VERSION ""

NS_ :

BS_:

BU_:

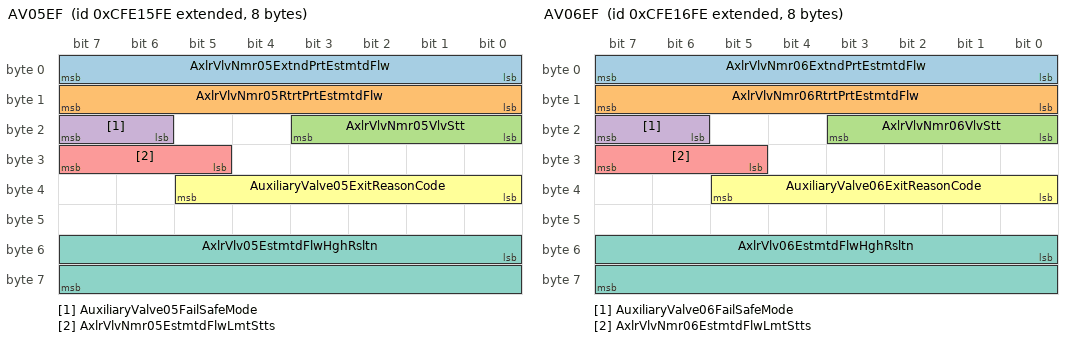
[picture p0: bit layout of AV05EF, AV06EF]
BO_ 2365462014 AV05EF: 8 Vector__XXX
 SG_ AxlrVlvNmr05ExtndPrtEstmtdFlw : 0|8@1+ (1,-125) [-125|125] "%" Vector__XXX
 SG_ AxlrVlvNmr05RtrtPrtEstmtdFlw : 8|8@1+ (1,-125) [-125|125] "%" Vector__XXX
 SG_ AxlrVlvNmr05VlvStt : 16|4@1+ (1,0) [0|15] "" Vector__XXX
 SG_ AuxiliaryValve05FailSafeMode : 22|2@1+ (1,0) [0|3] "" Vector__XXX
 SG_ AxlrVlvNmr05EstmtdFlwLmtStts : 29|3@1+ (1,0) [0|7] "" Vector__XXX
 SG_ AuxiliaryValve05ExitReasonCode : 32|6@1+ (1,0) [0|63] "" Vector__XXX
 SG_ AxlrVlv05EstmtdFlwHghRsltn : 48|16@1+ (0.004,-125) [-125|132.02] "%" Vector__XXX

BO_ 2365462270 AV06EF: 8 Vector__XXX
 SG_ AxlrVlvNmr06ExtndPrtEstmtdFlw : 0|8@1+ (1,-125) [-125|125] "%" Vector__XXX
 SG_ AxlrVlvNmr06RtrtPrtEstmtdFlw : 8|8@1+ (1,-125) [-125|125] "%" Vector__XXX
 SG_ AxlrVlvNmr06VlvStt : 16|4@1+ (1,0) [0|15] "" Vector__XXX
 SG_ AuxiliaryValve06FailSafeMode : 22|2@1+ (1,0) [0|3] "" Vector__XXX
 SG_ AxlrVlvNmr06EstmtdFlwLmtStts : 29|3@1+ (1,0) [0|7] "" Vector__XXX
 SG_ AuxiliaryValve06ExitReasonCode : 32|6@1+ (1,0) [0|63] "" Vector__XXX
 SG_ AxlrVlv06EstmtdFlwHghRsltn : 48|16@1+ (0.004,-125) [-125|132.02] "%" Vector__XXX

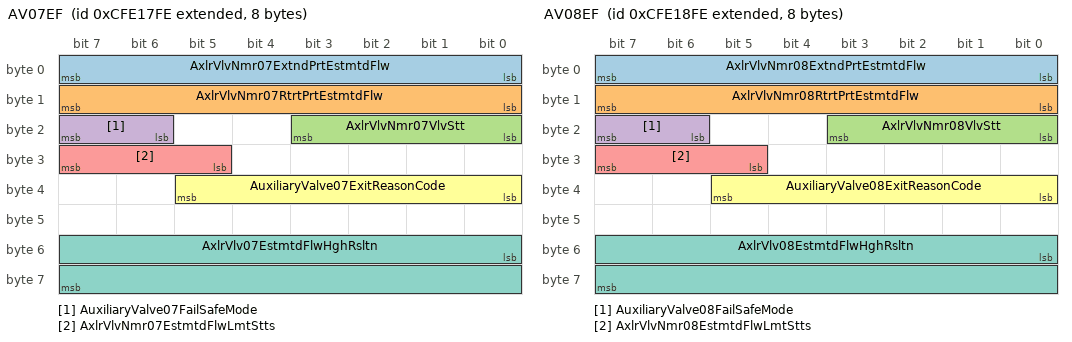
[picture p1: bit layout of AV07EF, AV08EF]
BO_ 2365462526 AV07EF: 8 Vector__XXX
 SG_ AxlrVlvNmr07ExtndPrtEstmtdFlw : 0|8@1+ (1,-125) [-125|125] "%" Vector__XXX
 SG_ AxlrVlvNmr07RtrtPrtEstmtdFlw : 8|8@1+ (1,-125) [-125|125] "%" Vector__XXX
 SG_ AxlrVlvNmr07VlvStt : 16|4@1+ (1,0) [0|15] "" Vector__XXX
 SG_ AuxiliaryValve07FailSafeMode : 22|2@1+ (1,0) [0|3] "" Vector__XXX
 SG_ AxlrVlvNmr07EstmtdFlwLmtStts : 29|3@1+ (1,0) [0|7] "" Vector__XXX
 SG_ AuxiliaryValve07ExitReasonCode : 32|6@1+ (1,0) [0|63] "" Vector__XXX
 SG_ AxlrVlv07EstmtdFlwHghRsltn : 48|16@1+ (0.004,-125) [-125|132.02] "%" Vector__XXX

BO_ 2365462782 AV08EF: 8 Vector__XXX
 SG_ AxlrVlvNmr08ExtndPrtEstmtdFlw : 0|8@1+ (1,-125) [-125|125] "%" Vector__XXX
 SG_ AxlrVlvNmr08RtrtPrtEstmtdFlw : 8|8@1+ (1,-125) [-125|125] "%" Vector__XXX
 SG_ AxlrVlvNmr08VlvStt : 16|4@1+ (1,0) [0|15] "" Vector__XXX
 SG_ AuxiliaryValve08FailSafeMode : 22|2@1+ (1,0) [0|3] "" Vector__XXX
 SG_ AxlrVlvNmr08EstmtdFlwLmtStts : 29|3@1+ (1,0) [0|7] "" Vector__XXX
 SG_ AuxiliaryValve08ExitReasonCode : 32|6@1+ (1,0) [0|63] "" Vector__XXX
 SG_ AxlrVlv08EstmtdFlwHghRsltn : 48|16@1+ (0.004,-125) [-125|132.02] "%" Vector__XXX

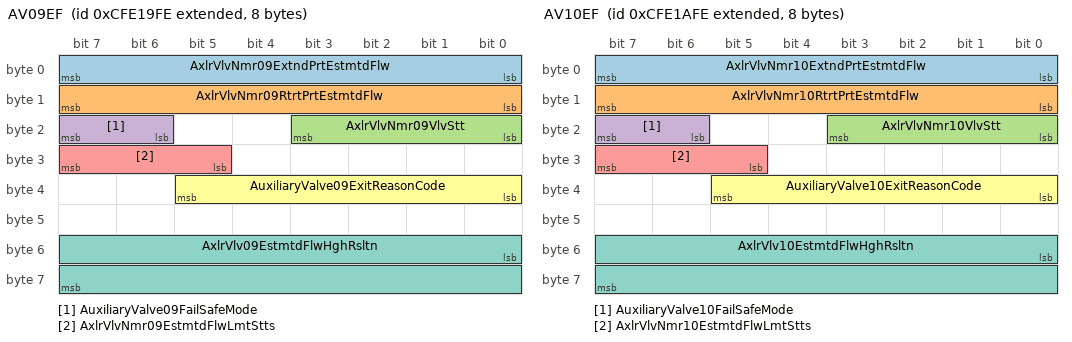
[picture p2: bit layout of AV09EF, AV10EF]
BO_ 2365463038 AV09EF: 8 Vector__XXX
 SG_ AxlrVlvNmr09ExtndPrtEstmtdFlw : 0|8@1+ (1,-125) [-125|125] "%" Vector__XXX
 SG_ AxlrVlvNmr09RtrtPrtEstmtdFlw : 8|8@1+ (1,-125) [-125|125] "%" Vector__XXX
 SG_ AxlrVlvNmr09VlvStt : 16|4@1+ (1,0) [0|15] "" Vector__XXX
 SG_ AuxiliaryValve09FailSafeMode : 22|2@1+ (1,0) [0|3] "" Vector__XXX
 SG_ AxlrVlvNmr09EstmtdFlwLmtStts : 29|3@1+ (1,0) [0|7] "" Vector__XXX
 SG_ AuxiliaryValve09ExitReasonCode : 32|6@1+ (1,0) [0|63] "" Vector__XXX
 SG_ AxlrVlv09EstmtdFlwHghRsltn : 48|16@1+ (0.004,-125) [-125|132.02] "%" Vector__XXX

BO_ 2365463294 AV10EF: 8 Vector__XXX
 SG_ AxlrVlvNmr10ExtndPrtEstmtdFlw : 0|8@1+ (1,-125) [-125|125] "%" Vector__XXX
 SG_ AxlrVlvNmr10RtrtPrtEstmtdFlw : 8|8@1+ (1,-125) [-125|125] "%" Vector__XXX
 SG_ AxlrVlvNmr10VlvStt : 16|4@1+ (1,0) [0|15] "" Vector__XXX
 SG_ AuxiliaryValve10FailSafeMode : 22|2@1+ (1,0) [0|3] "" Vector__XXX
 SG_ AxlrVlvNmr10EstmtdFlwLmtStts : 29|3@1+ (1,0) [0|7] "" Vector__XXX
 SG_ AuxiliaryValve10ExitReasonCode : 32|6@1+ (1,0) [0|63] "" Vector__XXX
 SG_ AxlrVlv10EstmtdFlwHghRsltn : 48|16@1+ (0.004,-125) [-125|132.02] "%" Vector__XXX

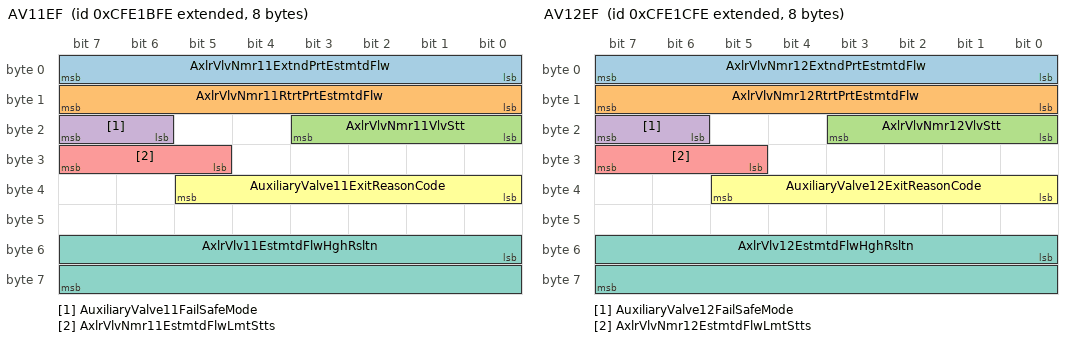
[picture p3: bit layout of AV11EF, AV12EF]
BO_ 2365463550 AV11EF: 8 Vector__XXX
 SG_ AxlrVlvNmr11ExtndPrtEstmtdFlw : 0|8@1+ (1,-125) [-125|125] "%" Vector__XXX
 SG_ AxlrVlvNmr11RtrtPrtEstmtdFlw : 8|8@1+ (1,-125) [-125|125] "%" Vector__XXX
 SG_ AxlrVlvNmr11VlvStt : 16|4@1+ (1,0) [0|15] "" Vector__XXX
 SG_ AuxiliaryValve11FailSafeMode : 22|2@1+ (1,0) [0|3] "" Vector__XXX
 SG_ AxlrVlvNmr11EstmtdFlwLmtStts : 29|3@1+ (1,0) [0|7] "" Vector__XXX
 SG_ AuxiliaryValve11ExitReasonCode : 32|6@1+ (1,0) [0|63] "" Vector__XXX
 SG_ AxlrVlv11EstmtdFlwHghRsltn : 48|16@1+ (0.004,-125) [-125|132.02] "%" Vector__XXX

BO_ 2365463806 AV12EF: 8 Vector__XXX
 SG_ AxlrVlvNmr12ExtndPrtEstmtdFlw : 0|8@1+ (1,-125) [-125|125] "%" Vector__XXX
 SG_ AxlrVlvNmr12RtrtPrtEstmtdFlw : 8|8@1+ (1,-125) [-125|125] "%" Vector__XXX
 SG_ AxlrVlvNmr12VlvStt : 16|4@1+ (1,0) [0|15] "" Vector__XXX
 SG_ AuxiliaryValve12FailSafeMode : 22|2@1+ (1,0) [0|3] "" Vector__XXX
 SG_ AxlrVlvNmr12EstmtdFlwLmtStts : 29|3@1+ (1,0) [0|7] "" Vector__XXX
 SG_ AuxiliaryValve12ExitReasonCode : 32|6@1+ (1,0) [0|63] "" Vector__XXX
 SG_ AxlrVlv12EstmtdFlwHghRsltn : 48|16@1+ (0.004,-125) [-125|132.02] "%" Vector__XXX

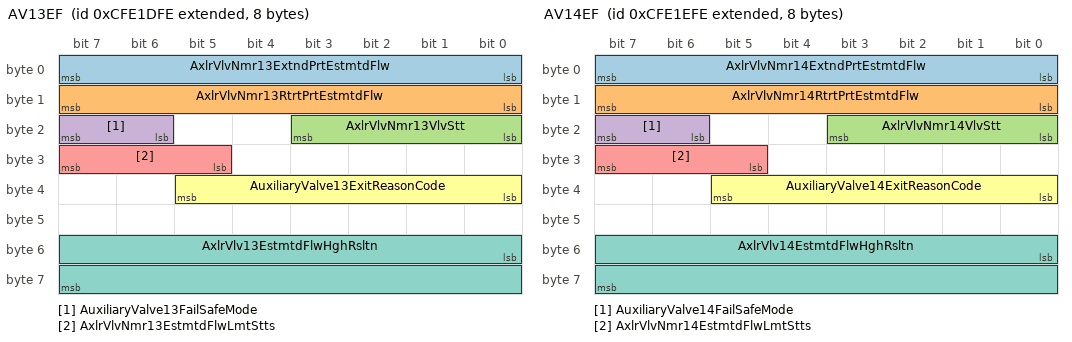
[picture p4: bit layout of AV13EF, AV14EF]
BO_ 2365464062 AV13EF: 8 Vector__XXX
 SG_ AxlrVlvNmr13ExtndPrtEstmtdFlw : 0|8@1+ (1,-125) [-125|125] "%" Vector__XXX
 SG_ AxlrVlvNmr13RtrtPrtEstmtdFlw : 8|8@1+ (1,-125) [-125|125] "%" Vector__XXX
 SG_ AxlrVlvNmr13VlvStt : 16|4@1+ (1,0) [0|15] "" Vector__XXX
 SG_ AuxiliaryValve13FailSafeMode : 22|2@1+ (1,0) [0|3] "" Vector__XXX
 SG_ AxlrVlvNmr13EstmtdFlwLmtStts : 29|3@1+ (1,0) [0|7] "" Vector__XXX
 SG_ AuxiliaryValve13ExitReasonCode : 32|6@1+ (1,0) [0|63] "" Vector__XXX
 SG_ AxlrVlv13EstmtdFlwHghRsltn : 48|16@1+ (0.004,-125) [-125|132.02] "%" Vector__XXX

BO_ 2365464318 AV14EF: 8 Vector__XXX
 SG_ AxlrVlvNmr14ExtndPrtEstmtdFlw : 0|8@1+ (1,-125) [-125|125] "%" Vector__XXX
 SG_ AxlrVlvNmr14RtrtPrtEstmtdFlw : 8|8@1+ (1,-125) [-125|125] "%" Vector__XXX
 SG_ AxlrVlvNmr14VlvStt : 16|4@1+ (1,0) [0|15] "" Vector__XXX
 SG_ AuxiliaryValve14FailSafeMode : 22|2@1+ (1,0) [0|3] "" Vector__XXX
 SG_ AxlrVlvNmr14EstmtdFlwLmtStts : 29|3@1+ (1,0) [0|7] "" Vector__XXX
 SG_ AuxiliaryValve14ExitReasonCode : 32|6@1+ (1,0) [0|63] "" Vector__XXX
 SG_ AxlrVlv14EstmtdFlwHghRsltn : 48|16@1+ (0.004,-125) [-125|132.02] "%" Vector__XXX

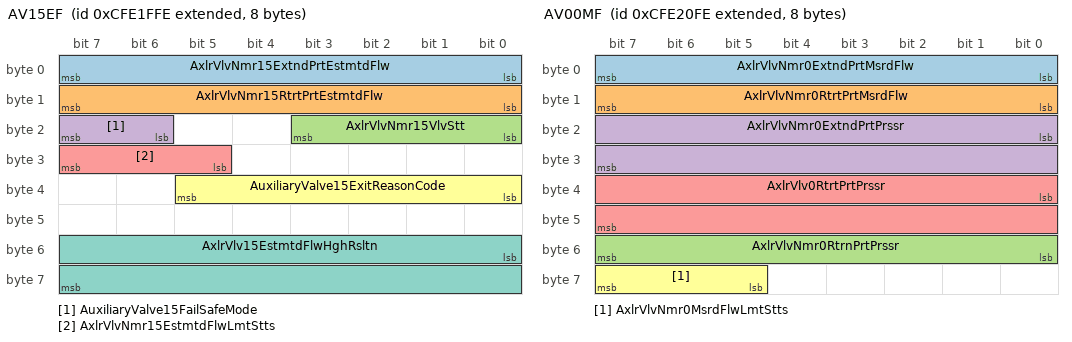
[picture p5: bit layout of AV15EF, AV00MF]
BO_ 2365464574 AV15EF: 8 Vector__XXX
 SG_ AxlrVlvNmr15ExtndPrtEstmtdFlw : 0|8@1+ (1,-125) [-125|125] "%" Vector__XXX
 SG_ AxlrVlvNmr15RtrtPrtEstmtdFlw : 8|8@1+ (1,-125) [-125|125] "%" Vector__XXX
 SG_ AxlrVlvNmr15VlvStt : 16|4@1+ (1,0) [0|15] "" Vector__XXX
 SG_ AuxiliaryValve15FailSafeMode : 22|2@1+ (1,0) [0|3] "" Vector__XXX
 SG_ AxlrVlvNmr15EstmtdFlwLmtStts : 29|3@1+ (1,0) [0|7] "" Vector__XXX
 SG_ AuxiliaryValve15ExitReasonCode : 32|6@1+ (1,0) [0|63] "" Vector__XXX
 SG_ AxlrVlv15EstmtdFlwHghRsltn : 48|16@1+ (0.004,-125) [-125|132.02] "%" Vector__XXX

BO_ 2365464830 AV00MF: 8 Vector__XXX
 SG_ AxlrVlvNmr0ExtndPrtMsrdFlw : 0|8@1+ (1,-125) [-125|125] "%" Vector__XXX
 SG_ AxlrVlvNmr0RtrtPrtMsrdFlw : 8|8@1+ (1,-125) [-125|125] "%" Vector__XXX
 SG_ AxlrVlvNmr0RtrnPrtPrssr : 48|8@1+ (16,0) [0|4000] "kPa" Vector__XXX
 SG_ AxlrVlvNmr0ExtndPrtPrssr : 16|16@1+ (5,0) [0|321275] "kPa" Vector__XXX
 SG_ AxlrVlv0RtrtPrtPrssr : 32|16@1+ (5,0) [0|321275] "kPa" Vector__XXX
 SG_ AxlrVlvNmr0MsrdFlwLmtStts : 61|3@1+ (1,0) [0|7] "" Vector__XXX

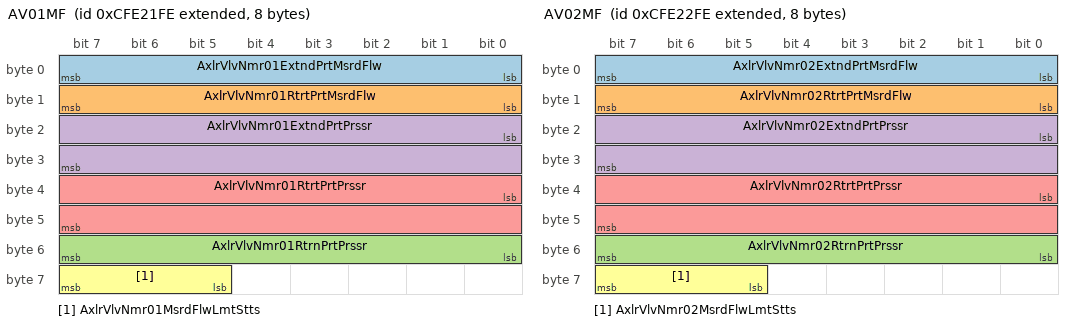
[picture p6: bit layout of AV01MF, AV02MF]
BO_ 2365465086 AV01MF: 8 Vector__XXX
 SG_ AxlrVlvNmr01ExtndPrtMsrdFlw : 0|8@1+ (1,-125) [-125|125] "%" Vector__XXX
 SG_ AxlrVlvNmr01RtrtPrtMsrdFlw : 8|8@1+ (1,-125) [-125|125] "%" Vector__XXX
 SG_ AxlrVlvNmr01RtrnPrtPrssr : 48|8@1+ (16,0) [0|4000] "kPa" Vector__XXX
 SG_ AxlrVlvNmr01ExtndPrtPrssr : 16|16@1+ (5,0) [0|321275] "kPa" Vector__XXX
 SG_ AxlrVlvNmr01RtrtPrtPrssr : 32|16@1+ (5,0) [0|321275] "kPa" Vector__XXX
 SG_ AxlrVlvNmr01MsrdFlwLmtStts : 61|3@1+ (1,0) [0|7] "" Vector__XXX

BO_ 2365465342 AV02MF: 8 Vector__XXX
 SG_ AxlrVlvNmr02ExtndPrtMsrdFlw : 0|8@1+ (1,-125) [-125|125] "%" Vector__XXX
 SG_ AxlrVlvNmr02RtrtPrtMsrdFlw : 8|8@1+ (1,-125) [-125|125] "%" Vector__XXX
 SG_ AxlrVlvNmr02RtrnPrtPrssr : 48|8@1+ (16,0) [0|4000] "kPa" Vector__XXX
 SG_ AxlrVlvNmr02ExtndPrtPrssr : 16|16@1+ (5,0) [0|321275] "kPa" Vector__XXX
 SG_ AxlrVlvNmr02RtrtPrtPrssr : 32|16@1+ (5,0) [0|321275] "kPa" Vector__XXX
 SG_ AxlrVlvNmr02MsrdFlwLmtStts : 61|3@1+ (1,0) [0|7] "" Vector__XXX

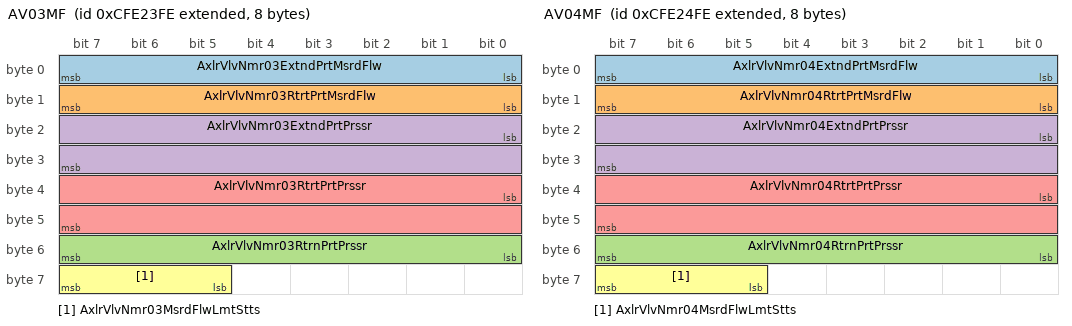
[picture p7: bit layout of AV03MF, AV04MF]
BO_ 2365465598 AV03MF: 8 Vector__XXX
 SG_ AxlrVlvNmr03ExtndPrtMsrdFlw : 0|8@1+ (1,-125) [-125|125] "%" Vector__XXX
 SG_ AxlrVlvNmr03RtrtPrtMsrdFlw : 8|8@1+ (1,-125) [-125|125] "%" Vector__XXX
 SG_ AxlrVlvNmr03RtrnPrtPrssr : 48|8@1+ (16,0) [0|4000] "kPa" Vector__XXX
 SG_ AxlrVlvNmr03ExtndPrtPrssr : 16|16@1+ (5,0) [0|321275] "kPa" Vector__XXX
 SG_ AxlrVlvNmr03RtrtPrtPrssr : 32|16@1+ (5,0) [0|321275] "kPa" Vector__XXX
 SG_ AxlrVlvNmr03MsrdFlwLmtStts : 61|3@1+ (1,0) [0|7] "" Vector__XXX

BO_ 2365465854 AV04MF: 8 Vector__XXX
 SG_ AxlrVlvNmr04ExtndPrtMsrdFlw : 0|8@1+ (1,-125) [-125|125] "%" Vector__XXX
 SG_ AxlrVlvNmr04RtrtPrtMsrdFlw : 8|8@1+ (1,-125) [-125|125] "%" Vector__XXX
 SG_ AxlrVlvNmr04RtrnPrtPrssr : 48|8@1+ (16,0) [0|4000] "kPa" Vector__XXX
 SG_ AxlrVlvNmr04ExtndPrtPrssr : 16|16@1+ (5,0) [0|321275] "kPa" Vector__XXX
 SG_ AxlrVlvNmr04RtrtPrtPrssr : 32|16@1+ (5,0) [0|321275] "kPa" Vector__XXX
 SG_ AxlrVlvNmr04MsrdFlwLmtStts : 61|3@1+ (1,0) [0|7] "" Vector__XXX

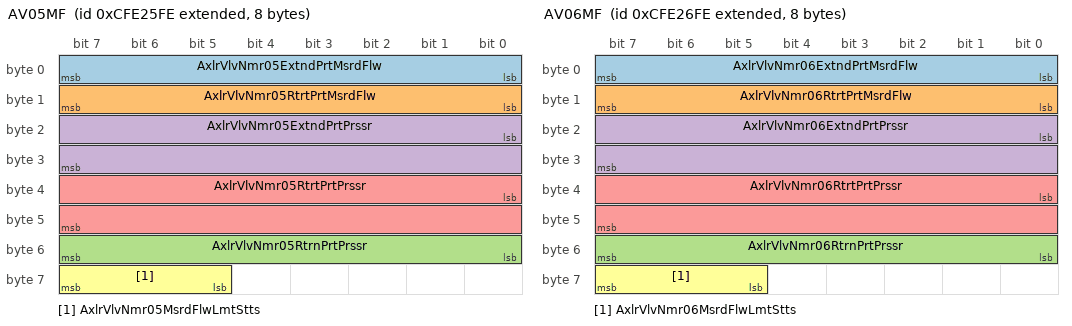
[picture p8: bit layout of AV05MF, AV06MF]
BO_ 2365466110 AV05MF: 8 Vector__XXX
 SG_ AxlrVlvNmr05ExtndPrtMsrdFlw : 0|8@1+ (1,-125) [-125|125] "%" Vector__XXX
 SG_ AxlrVlvNmr05RtrtPrtMsrdFlw : 8|8@1+ (1,-125) [-125|125] "%" Vector__XXX
 SG_ AxlrVlvNmr05RtrnPrtPrssr : 48|8@1+ (16,0) [0|4000] "kPa" Vector__XXX
 SG_ AxlrVlvNmr05ExtndPrtPrssr : 16|16@1+ (5,0) [0|321275] "kPa" Vector__XXX
 SG_ AxlrVlvNmr05RtrtPrtPrssr : 32|16@1+ (5,0) [0|321275] "kPa" Vector__XXX
 SG_ AxlrVlvNmr05MsrdFlwLmtStts : 61|3@1+ (1,0) [0|7] "" Vector__XXX

BO_ 2365466366 AV06MF: 8 Vector__XXX
 SG_ AxlrVlvNmr06ExtndPrtMsrdFlw : 0|8@1+ (1,-125) [-125|125] "%" Vector__XXX
 SG_ AxlrVlvNmr06RtrtPrtMsrdFlw : 8|8@1+ (1,-125) [-125|125] "%" Vector__XXX
 SG_ AxlrVlvNmr06RtrnPrtPrssr : 48|8@1+ (16,0) [0|4000] "kPa" Vector__XXX
 SG_ AxlrVlvNmr06ExtndPrtPrssr : 16|16@1+ (5,0) [0|321275] "kPa" Vector__XXX
 SG_ AxlrVlvNmr06RtrtPrtPrssr : 32|16@1+ (5,0) [0|321275] "kPa" Vector__XXX
 SG_ AxlrVlvNmr06MsrdFlwLmtStts : 61|3@1+ (1,0) [0|7] "" Vector__XXX

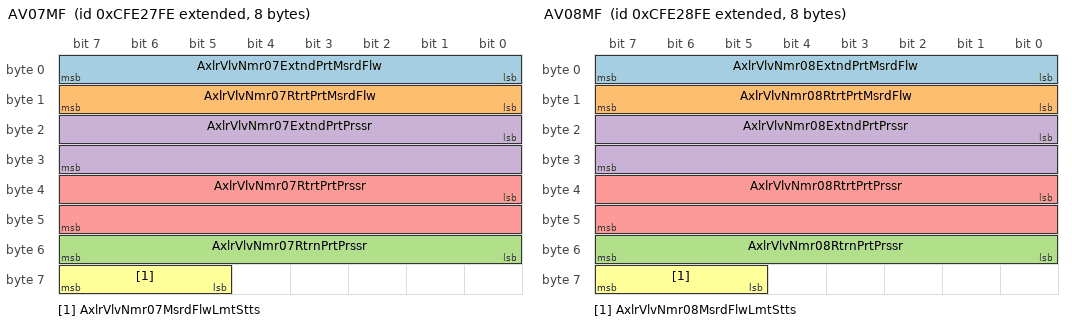
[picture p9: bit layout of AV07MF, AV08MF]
BO_ 2365466622 AV07MF: 8 Vector__XXX
 SG_ AxlrVlvNmr07ExtndPrtMsrdFlw : 0|8@1+ (1,-125) [-125|125] "%" Vector__XXX
 SG_ AxlrVlvNmr07RtrtPrtMsrdFlw : 8|8@1+ (1,-125) [-125|125] "%" Vector__XXX
 SG_ AxlrVlvNmr07RtrnPrtPrssr : 48|8@1+ (16,0) [0|4000] "kPa" Vector__XXX
 SG_ AxlrVlvNmr07ExtndPrtPrssr : 16|16@1+ (5,0) [0|321275] "kPa" Vector__XXX
 SG_ AxlrVlvNmr07RtrtPrtPrssr : 32|16@1+ (5,0) [0|321275] "kPa" Vector__XXX
 SG_ AxlrVlvNmr07MsrdFlwLmtStts : 61|3@1+ (1,0) [0|7] "" Vector__XXX

BO_ 2365466878 AV08MF: 8 Vector__XXX
 SG_ AxlrVlvNmr08ExtndPrtMsrdFlw : 0|8@1+ (1,-125) [-125|125] "%" Vector__XXX
 SG_ AxlrVlvNmr08RtrtPrtMsrdFlw : 8|8@1+ (1,-125) [-125|125] "%" Vector__XXX
 SG_ AxlrVlvNmr08RtrnPrtPrssr : 48|8@1+ (16,0) [0|4000] "kPa" Vector__XXX
 SG_ AxlrVlvNmr08ExtndPrtPrssr : 16|16@1+ (5,0) [0|321275] "kPa" Vector__XXX
 SG_ AxlrVlvNmr08RtrtPrtPrssr : 32|16@1+ (5,0) [0|321275] "kPa" Vector__XXX
 SG_ AxlrVlvNmr08MsrdFlwLmtStts : 61|3@1+ (1,0) [0|7] "" Vector__XXX

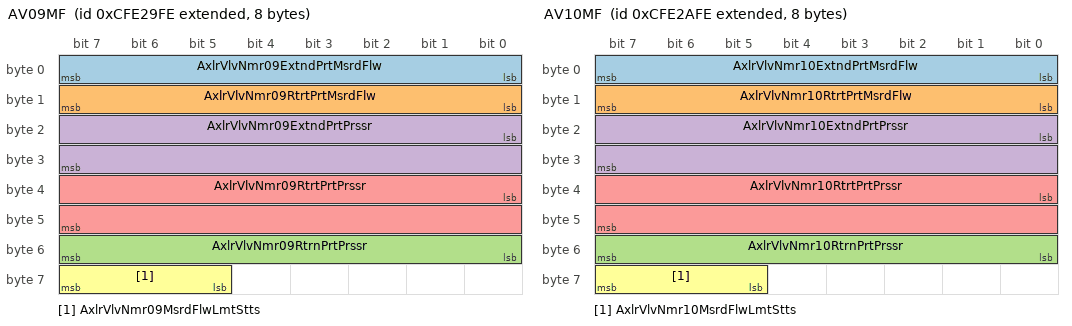
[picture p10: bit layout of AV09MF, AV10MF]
BO_ 2365467134 AV09MF: 8 Vector__XXX
 SG_ AxlrVlvNmr09ExtndPrtMsrdFlw : 0|8@1+ (1,-125) [-125|125] "%" Vector__XXX
 SG_ AxlrVlvNmr09RtrtPrtMsrdFlw : 8|8@1+ (1,-125) [-125|125] "%" Vector__XXX
 SG_ AxlrVlvNmr09RtrnPrtPrssr : 48|8@1+ (16,0) [0|4000] "kPa" Vector__XXX
 SG_ AxlrVlvNmr09ExtndPrtPrssr : 16|16@1+ (5,0) [0|321275] "kPa" Vector__XXX
 SG_ AxlrVlvNmr09RtrtPrtPrssr : 32|16@1+ (5,0) [0|321275] "kPa" Vector__XXX
 SG_ AxlrVlvNmr09MsrdFlwLmtStts : 61|3@1+ (1,0) [0|7] "" Vector__XXX

BO_ 2365467390 AV10MF: 8 Vector__XXX
 SG_ AxlrVlvNmr10ExtndPrtMsrdFlw : 0|8@1+ (1,-125) [-125|125] "%" Vector__XXX
 SG_ AxlrVlvNmr10RtrtPrtMsrdFlw : 8|8@1+ (1,-125) [-125|125] "%" Vector__XXX
 SG_ AxlrVlvNmr10RtrnPrtPrssr : 48|8@1+ (16,0) [0|4000] "kPa" Vector__XXX
 SG_ AxlrVlvNmr10ExtndPrtPrssr : 16|16@1+ (5,0) [0|321275] "kPa" Vector__XXX
 SG_ AxlrVlvNmr10RtrtPrtPrssr : 32|16@1+ (5,0) [0|321275] "kPa" Vector__XXX
 SG_ AxlrVlvNmr10MsrdFlwLmtStts : 61|3@1+ (1,0) [0|7] "" Vector__XXX

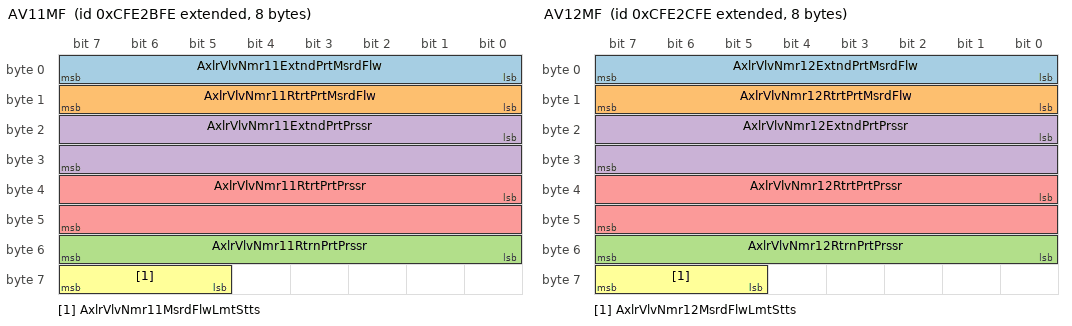
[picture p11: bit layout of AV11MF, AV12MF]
BO_ 2365467646 AV11MF: 8 Vector__XXX
 SG_ AxlrVlvNmr11ExtndPrtMsrdFlw : 0|8@1+ (1,-125) [-125|125] "%" Vector__XXX
 SG_ AxlrVlvNmr11RtrtPrtMsrdFlw : 8|8@1+ (1,-125) [-125|125] "%" Vector__XXX
 SG_ AxlrVlvNmr11RtrnPrtPrssr : 48|8@1+ (16,0) [0|4000] "kPa" Vector__XXX
 SG_ AxlrVlvNmr11ExtndPrtPrssr : 16|16@1+ (5,0) [0|321275] "kPa" Vector__XXX
 SG_ AxlrVlvNmr11RtrtPrtPrssr : 32|16@1+ (5,0) [0|321275] "kPa" Vector__XXX
 SG_ AxlrVlvNmr11MsrdFlwLmtStts : 61|3@1+ (1,0) [0|7] "" Vector__XXX

BO_ 2365467902 AV12MF: 8 Vector__XXX
 SG_ AxlrVlvNmr12ExtndPrtMsrdFlw : 0|8@1+ (1,-125) [-125|125] "%" Vector__XXX
 SG_ AxlrVlvNmr12RtrtPrtMsrdFlw : 8|8@1+ (1,-125) [-125|125] "%" Vector__XXX
 SG_ AxlrVlvNmr12RtrnPrtPrssr : 48|8@1+ (16,0) [0|4000] "kPa" Vector__XXX
 SG_ AxlrVlvNmr12ExtndPrtPrssr : 16|16@1+ (5,0) [0|321275] "kPa" Vector__XXX
 SG_ AxlrVlvNmr12RtrtPrtPrssr : 32|16@1+ (5,0) [0|321275] "kPa" Vector__XXX
 SG_ AxlrVlvNmr12MsrdFlwLmtStts : 61|3@1+ (1,0) [0|7] "" Vector__XXX

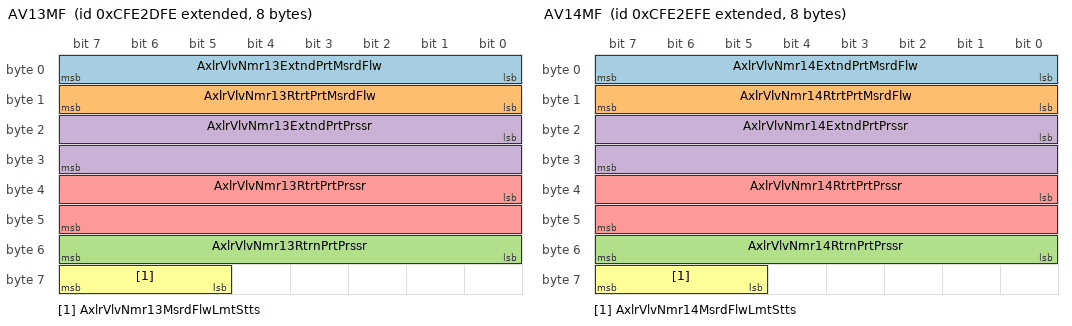
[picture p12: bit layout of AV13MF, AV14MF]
BO_ 2365468158 AV13MF: 8 Vector__XXX
 SG_ AxlrVlvNmr13ExtndPrtMsrdFlw : 0|8@1+ (1,-125) [-125|125] "%" Vector__XXX
 SG_ AxlrVlvNmr13RtrtPrtMsrdFlw : 8|8@1+ (1,-125) [-125|125] "%" Vector__XXX
 SG_ AxlrVlvNmr13RtrnPrtPrssr : 48|8@1+ (16,0) [0|4000] "kPa" Vector__XXX
 SG_ AxlrVlvNmr13ExtndPrtPrssr : 16|16@1+ (5,0) [0|321275] "kPa" Vector__XXX
 SG_ AxlrVlvNmr13RtrtPrtPrssr : 32|16@1+ (5,0) [0|321275] "kPa" Vector__XXX
 SG_ AxlrVlvNmr13MsrdFlwLmtStts : 61|3@1+ (1,0) [0|7] "" Vector__XXX

BO_ 2365468414 AV14MF: 8 Vector__XXX
 SG_ AxlrVlvNmr14ExtndPrtMsrdFlw : 0|8@1+ (1,-125) [-125|125] "%" Vector__XXX
 SG_ AxlrVlvNmr14RtrtPrtMsrdFlw : 8|8@1+ (1,-125) [-125|125] "%" Vector__XXX
 SG_ AxlrVlvNmr14RtrnPrtPrssr : 48|8@1+ (16,0) [0|4000] "kPa" Vector__XXX
 SG_ AxlrVlvNmr14ExtndPrtPrssr : 16|16@1+ (5,0) [0|321275] "kPa" Vector__XXX
 SG_ AxlrVlvNmr14RtrtPrtPrssr : 32|16@1+ (5,0) [0|321275] "kPa" Vector__XXX
 SG_ AxlrVlvNmr14MsrdFlwLmtStts : 61|3@1+ (1,0) [0|7] "" Vector__XXX

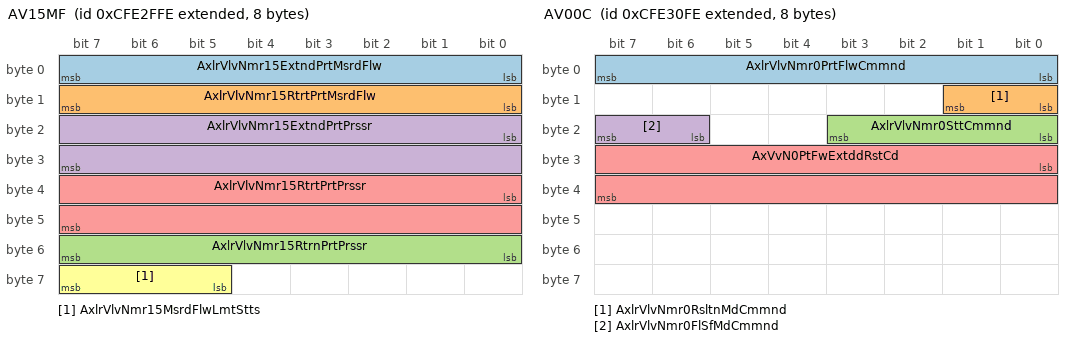
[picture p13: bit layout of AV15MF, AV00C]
BO_ 2365468670 AV15MF: 8 Vector__XXX
 SG_ AxlrVlvNmr15ExtndPrtMsrdFlw : 0|8@1+ (1,-125) [-125|125] "%" Vector__XXX
 SG_ AxlrVlvNmr15RtrtPrtMsrdFlw : 8|8@1+ (1,-125) [-125|125] "%" Vector__XXX
 SG_ AxlrVlvNmr15RtrnPrtPrssr : 48|8@1+ (16,0) [0|4000] "kPa" Vector__XXX
 SG_ AxlrVlvNmr15ExtndPrtPrssr : 16|16@1+ (5,0) [0|321275] "kPa" Vector__XXX
 SG_ AxlrVlvNmr15RtrtPrtPrssr : 32|16@1+ (5,0) [0|321275] "kPa" Vector__XXX
 SG_ AxlrVlvNmr15MsrdFlwLmtStts : 61|3@1+ (1,0) [0|7] "" Vector__XXX

BO_ 2365468926 AV00C: 8 Vector__XXX
 SG_ AxlrVlvNmr0PrtFlwCmmnd : 0|8@1+ (0.4,0) [0|100] "%" Vector__XXX
 SG_ AxlrVlvNmr0RsltnMdCmmnd : 8|2@1+ (1,0) [0|3] "" Vector__XXX
 SG_ AxlrVlvNmr0SttCmmnd : 16|4@1+ (1,0) [0|15] "" Vector__XXX
 SG_ AxlrVlvNmr0FlSfMdCmmnd : 22|2@1+ (1,0) [0|3] "" Vector__XXX
 SG_ AxVvN0PtFwExtddRstCd : 24|16@1+ (0.0015625,0) [0|100.3984375] "%" Vector__XXX

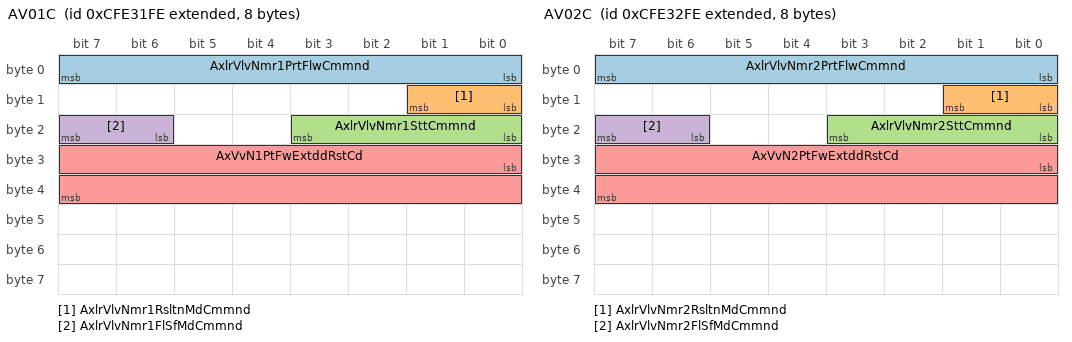
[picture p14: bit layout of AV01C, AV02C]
BO_ 2365469182 AV01C: 8 Vector__XXX
 SG_ AxlrVlvNmr1PrtFlwCmmnd : 0|8@1+ (0.4,0) [0|100] "%" Vector__XXX
 SG_ AxlrVlvNmr1RsltnMdCmmnd : 8|2@1+ (1,0) [0|3] "" Vector__XXX
 SG_ AxlrVlvNmr1SttCmmnd : 16|4@1+ (1,0) [0|15] "" Vector__XXX
 SG_ AxlrVlvNmr1FlSfMdCmmnd : 22|2@1+ (1,0) [0|3] "" Vector__XXX
 SG_ AxVvN1PtFwExtddRstCd : 24|16@1+ (0.0015625,0) [0|100.3984375] "%" Vector__XXX

BO_ 2365469438 AV02C: 8 Vector__XXX
 SG_ AxlrVlvNmr2PrtFlwCmmnd : 0|8@1+ (0.4,0) [0|100] "%" Vector__XXX
 SG_ AxlrVlvNmr2RsltnMdCmmnd : 8|2@1+ (1,0) [0|3] "" Vector__XXX
 SG_ AxlrVlvNmr2SttCmmnd : 16|4@1+ (1,0) [0|15] "" Vector__XXX
 SG_ AxlrVlvNmr2FlSfMdCmmnd : 22|2@1+ (1,0) [0|3] "" Vector__XXX
 SG_ AxVvN2PtFwExtddRstCd : 24|16@1+ (0.0015625,0) [0|100.3984375] "%" Vector__XXX

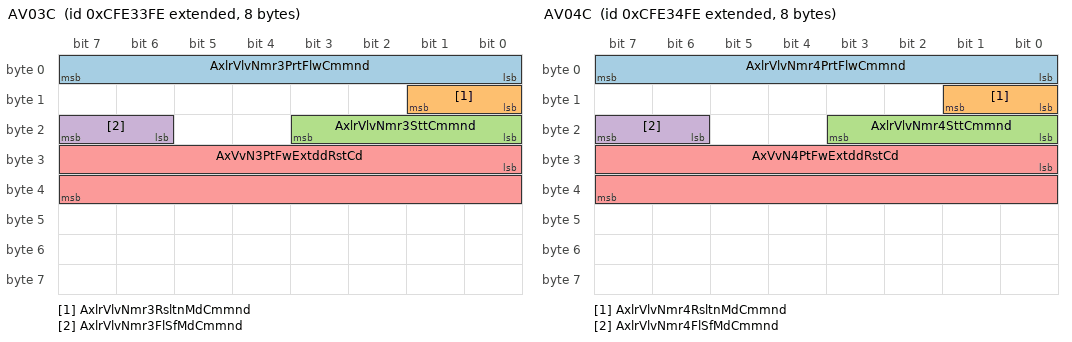
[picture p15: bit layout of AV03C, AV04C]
BO_ 2365469694 AV03C: 8 Vector__XXX
 SG_ AxlrVlvNmr3PrtFlwCmmnd : 0|8@1+ (0.4,0) [0|100] "%" Vector__XXX
 SG_ AxlrVlvNmr3RsltnMdCmmnd : 8|2@1+ (1,0) [0|3] "" Vector__XXX
 SG_ AxlrVlvNmr3SttCmmnd : 16|4@1+ (1,0) [0|15] "" Vector__XXX
 SG_ AxlrVlvNmr3FlSfMdCmmnd : 22|2@1+ (1,0) [0|3] "" Vector__XXX
 SG_ AxVvN3PtFwExtddRstCd : 24|16@1+ (0.0015625,0) [0|100.3984375] "%" Vector__XXX

BO_ 2365469950 AV04C: 8 Vector__XXX
 SG_ AxlrVlvNmr4PrtFlwCmmnd : 0|8@1+ (0.4,0) [0|100] "%" Vector__XXX
 SG_ AxlrVlvNmr4RsltnMdCmmnd : 8|2@1+ (1,0) [0|3] "" Vector__XXX
 SG_ AxlrVlvNmr4SttCmmnd : 16|4@1+ (1,0) [0|15] "" Vector__XXX
 SG_ AxlrVlvNmr4FlSfMdCmmnd : 22|2@1+ (1,0) [0|3] "" Vector__XXX
 SG_ AxVvN4PtFwExtddRstCd : 24|16@1+ (0.0015625,0) [0|100.3984375] "%" Vector__XXX

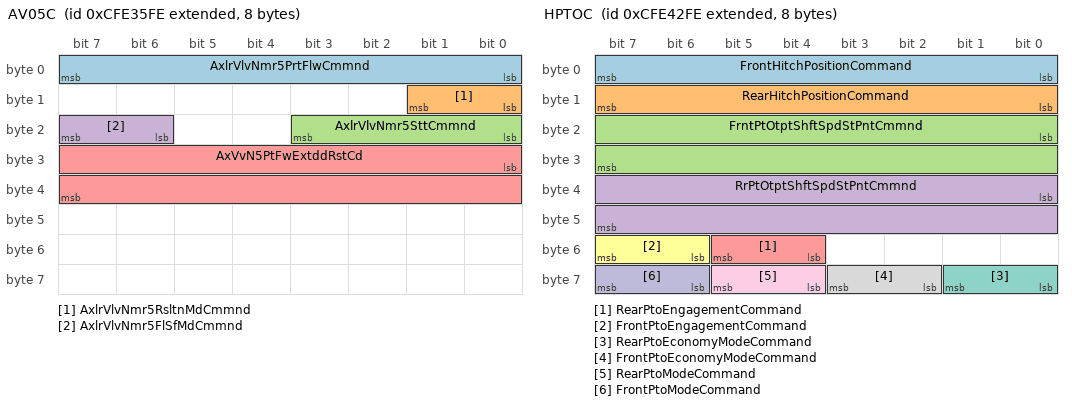
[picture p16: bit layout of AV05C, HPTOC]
BO_ 2365470206 AV05C: 8 Vector__XXX
 SG_ AxlrVlvNmr5PrtFlwCmmnd : 0|8@1+ (0.4,0) [0|100] "%" Vector__XXX
 SG_ AxlrVlvNmr5RsltnMdCmmnd : 8|2@1+ (1,0) [0|3] "" Vector__XXX
 SG_ AxlrVlvNmr5SttCmmnd : 16|4@1+ (1,0) [0|15] "" Vector__XXX
 SG_ AxlrVlvNmr5FlSfMdCmmnd : 22|2@1+ (1,0) [0|3] "" Vector__XXX
 SG_ AxVvN5PtFwExtddRstCd : 24|16@1+ (0.0015625,0) [0|100.3984375] "%" Vector__XXX

BO_ 2365470462 AV06C: 8 Vector__XXX
 SG_ AxlrVlvNmr6PrtFlwCmmnd : 0|8@1+ (0.4,0) [0|100] "%" Vector__XXX
 SG_ AxlrVlvNmr6RsltnMdCmmnd : 8|2@1+ (1,0) [0|3] "" Vector__XXX
 SG_ AxlrVlvNmr6SttCmmnd : 16|4@1+ (1,0) [0|15] "" Vector__XXX
 SG_ AxlrVlvNmr6FlSfMdCmmnd : 22|2@1+ (1,0) [0|3] "" Vector__XXX
 SG_ AxVvN6PtFwExtddRstCd : 24|16@1+ (0.0015625,0) [0|100.3984375] "%" Vector__XXX

BO_ 2365470718 AV07C: 8 Vector__XXX
 SG_ AxlrVlvNmr7PrtFlwCmmnd : 0|8@1+ (0.4,0) [0|100] "%" Vector__XXX
 SG_ AxlrVlvNmr7RsltnMdCmmnd : 8|2@1+ (1,0) [0|3] "" Vector__XXX
 SG_ AxlrVlvNmr7SttCmmnd : 16|4@1+ (1,0) [0|15] "" Vector__XXX
 SG_ AxlrVlvNmr7FlSfMdCmmnd : 22|2@1+ (1,0) [0|3] "" Vector__XXX
 SG_ AxVvN7PtFwExtddRstCd : 24|16@1+ (0.0015625,0) [0|100.3984375] "%" Vector__XXX

BO_ 2365470974 AV08C: 8 Vector__XXX
 SG_ AxlrVlvNmr8PrtFlwCmmnd : 0|8@1+ (0.4,0) [0|100] "%" Vector__XXX
 SG_ AxlrVlvNmr8RsltnMdCmmnd : 8|2@1+ (1,0) [0|3] "" Vector__XXX
 SG_ AxlrVlvNmr8SttCmmnd : 16|4@1+ (1,0) [0|15] "" Vector__XXX
 SG_ AxlrVlvNmr8FlSfMdCmmnd : 22|2@1+ (1,0) [0|3] "" Vector__XXX
 SG_ AxVvN8PtFwExtddRstCd : 24|16@1+ (0.0015625,0) [0|100.3984375] "%" Vector__XXX

BO_ 2365471230 AV09C: 8 Vector__XXX
 SG_ AxlrVlvNmr9PrtFlwCmmnd : 0|8@1+ (0.4,0) [0|100] "%" Vector__XXX
 SG_ AxlrVlvNmr9RsltnMdCmmnd : 8|2@1+ (1,0) [0|3] "" Vector__XXX
 SG_ AxlrVlvNmr9SttCmmnd : 16|4@1+ (1,0) [0|15] "" Vector__XXX
 SG_ AxlrVlvNmr9FlSfMdCmmnd : 22|2@1+ (1,0) [0|3] "" Vector__XXX
 SG_ AxVvN9PtFwExtddRstCd : 24|16@1+ (0.0015625,0) [0|100.3984375] "%" Vector__XXX

BO_ 2365471486 AV10C: 8 Vector__XXX
 SG_ AxlrVlvNmr10PrtFlwCmmnd : 0|8@1+ (0.4,0) [0|100] "%" Vector__XXX
 SG_ AxlrVlvNmr10RsltnMdCmmnd : 8|2@1+ (1,0) [0|3] "" Vector__XXX
 SG_ AxlrVlvNmr10SttCmmnd : 16|4@1+ (1,0) [0|15] "" Vector__XXX
 SG_ AxlrVlvNmr10FlSfMdCmmnd : 22|2@1+ (1,0) [0|3] "" Vector__XXX
 SG_ AxVvN10PtFwExtddRstCd : 24|16@1+ (0.0015625,0) [0|100.3984375] "%" Vector__XXX

BO_ 2365471742 AV11C: 8 Vector__XXX
 SG_ AxlrVlvNmr11PrtFlwCmmnd : 0|8@1+ (0.4,0) [0|100] "%" Vector__XXX
 SG_ AxlrVlvNmr11RsltnMdCmmnd : 8|2@1+ (1,0) [0|3] "" Vector__XXX
 SG_ AxlrVlvNmr11SttCmmnd : 16|4@1+ (1,0) [0|15] "" Vector__XXX
 SG_ AxlrVlvNmr11FlSfMdCmmnd : 22|2@1+ (1,0) [0|3] "" Vector__XXX
 SG_ AxVvN11PtFwExtddRstCd : 24|16@1+ (0.0015625,0) [0|100.3984375] "%" Vector__XXX

BO_ 2365471998 AV12C: 8 Vector__XXX
 SG_ AxlrVlvNmr12PrtFlwCmmnd : 0|8@1+ (0.4,0) [0|100] "%" Vector__XXX
 SG_ AxlrVlvNmr12RsltnMdCmmnd : 8|2@1+ (1,0) [0|3] "" Vector__XXX
 SG_ AxlrVlvNmr12SttCmmnd : 16|4@1+ (1,0) [0|15] "" Vector__XXX
 SG_ AxlrVlvNmr12FlSfMdCmmnd : 22|2@1+ (1,0) [0|3] "" Vector__XXX
 SG_ AxVvN12PtFwExtddRstCd : 24|16@1+ (0.0015625,0) [0|100.3984375] "%" Vector__XXX

BO_ 2365472254 AV13C: 8 Vector__XXX
 SG_ AxlrVlvNmr13PrtFlwCmmnd : 0|8@1+ (0.4,0) [0|100] "%" Vector__XXX
 SG_ AxlrVlvNmr13RsltnMdCmmnd : 8|2@1+ (1,0) [0|3] "" Vector__XXX
 SG_ AxlrVlvNmr13SttCmmnd : 16|4@1+ (1,0) [0|15] "" Vector__XXX
 SG_ AxlrVlvNmr13FlSfMdCmmnd : 22|2@1+ (1,0) [0|3] "" Vector__XXX
 SG_ AxVvN13PtFwExtddRstCd : 24|16@1+ (0.0015625,0) [0|100.3984375] "%" Vector__XXX

BO_ 2365472510 AV14C: 8 Vector__XXX
 SG_ AxlrVlvNmr14PrtFlwCmmnd : 0|8@1+ (0.4,0) [0|100] "%" Vector__XXX
 SG_ AxlrVlvNmr14RsltnMdCmmnd : 8|2@1+ (1,0) [0|3] "" Vector__XXX
 SG_ AxlrVlvNmr14SttCmmnd : 16|4@1+ (1,0) [0|15] "" Vector__XXX
 SG_ AxlrVlvNmr14FlSfMdCmmnd : 22|2@1+ (1,0) [0|3] "" Vector__XXX
 SG_ AxVvN14PtFwExtddRstCd : 24|16@1+ (0.0015625,0) [0|100.3984375] "%" Vector__XXX

BO_ 2365472766 AV15C: 8 Vector__XXX
 SG_ AxlrVlvNmr15PrtFlwCmmnd : 0|8@1+ (0.4,0) [0|100] "%" Vector__XXX
 SG_ AxlrVlvNmr15RsltnMdCmmnd : 8|2@1+ (1,0) [0|3] "" Vector__XXX
 SG_ AxlrVlvNmr15SttCmmnd : 16|4@1+ (1,0) [0|15] "" Vector__XXX
 SG_ AxlrVlvNmr15FlSfMdCmmnd : 22|2@1+ (1,0) [0|3] "" Vector__XXX
 SG_ AxVvN15PtFwExtddRstCd : 24|16@1+ (0.0015625,0) [0|100.3984375] "%" Vector__XXX

BO_ 2365473534 HPTOC: 8 Vector__XXX
 SG_ FrontHitchPositionCommand : 0|8@1+ (0.4,0) [0|100] "%" Vector__XXX
 SG_ RearHitchPositionCommand : 8|8@1+ (0.4,0) [0|100] "%" Vector__XXX
 SG_ FrntPtOtptShftSpdStPntCmmnd : 16|16@1+ (0.125,0) [0|8031.875] "1/min" Vector__XXX
 SG_ RrPtOtptShftSpdStPntCmmnd : 32|16@1+ (0.125,0) [0|8031.875] "1/min" Vector__XXX
 SG_ RearPtoEngagementCommand : 52|2@1+ (1,0) [0|3] "" Vector__XXX
 SG_ FrontPtoEngagementCommand : 54|2@1+ (1,0) [0|3] "" Vector__XXX
 SG_ RearPtoEconomyModeCommand : 56|2@1+ (1,0) [0|3] "" Vector__XXX
 SG_ FrontPtoEconomyModeCommand : 58|2@1+ (1,0) [0|3] "" Vector__XXX
 SG_ RearPtoModeCommand : 60|2@1+ (1,0) [0|3] "" Vector__XXX
 SG_ FrontPtoModeCommand : 62|2@1+ (1,0) [0|3] "" Vector__XXX

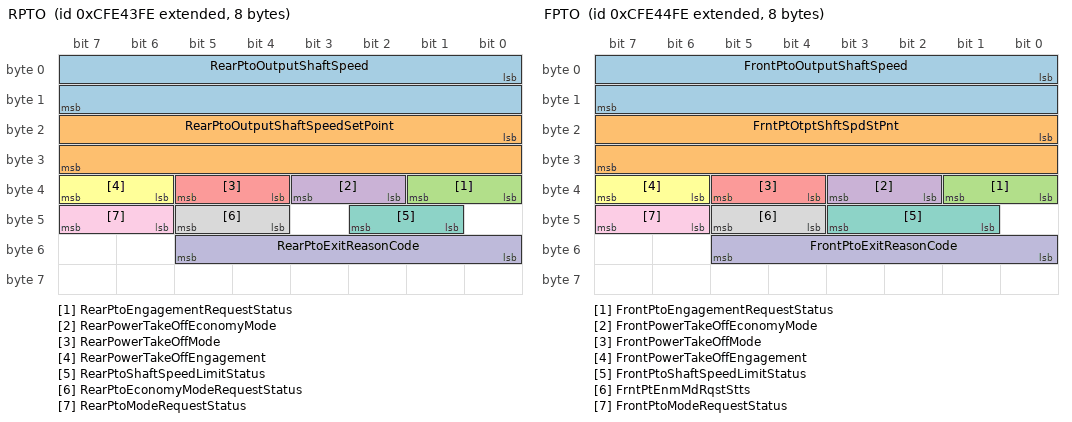
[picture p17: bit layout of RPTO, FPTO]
BO_ 2365473790 RPTO: 8 Vector__XXX
 SG_ RearPtoOutputShaftSpeed : 0|16@1+ (0.125,0) [0|8031.875] "1/min/bit" Vector__XXX
 SG_ RearPtoOutputShaftSpeedSetPoint : 16|16@1+ (0.125,0) [0|8031.875] "1/min/bit" Vector__XXX
 SG_ RearPtoEngagementRequestStatus : 32|2@1+ (1,0) [0|3] "" Vector__XXX
 SG_ RearPowerTakeOffEconomyMode : 34|2@1+ (1,0) [0|3] "" Vector__XXX
 SG_ RearPowerTakeOffMode : 36|2@1+ (1,0) [0|3] "" Vector__XXX
 SG_ RearPowerTakeOffEngagement : 38|2@1+ (1,0) [0|3] "" Vector__XXX
 SG_ RearPtoShaftSpeedLimitStatus : 41|2@1+ (1,0) [0|7] "" Vector__XXX
 SG_ RearPtoEconomyModeRequestStatus : 44|2@1+ (1,0) [0|3] "" Vector__XXX
 SG_ RearPtoModeRequestStatus : 46|2@1+ (1,0) [0|3] "" Vector__XXX
 SG_ RearPtoExitReasonCode : 48|6@1+ (1,0) [0|63] "" Vector__XXX

BO_ 2365474046 FPTO: 8 Vector__XXX
 SG_ FrontPtoOutputShaftSpeed : 0|16@1+ (0.125,0) [0|8031.875] "1/min/bit" Vector__XXX
 SG_ FrntPtOtptShftSpdStPnt : 16|16@1+ (0.125,0) [0|8031.875] "1/min/bit" Vector__XXX
 SG_ FrontPtoEngagementRequestStatus : 32|2@1+ (1,0) [0|3] "" Vector__XXX
 SG_ FrontPowerTakeOffEconomyMode : 34|2@1+ (1,0) [0|3] "" Vector__XXX
 SG_ FrontPowerTakeOffMode : 36|2@1+ (1,0) [0|3] "" Vector__XXX
 SG_ FrontPowerTakeOffEngagement : 38|2@1+ (1,0) [0|3] "" Vector__XXX
 SG_ FrontPtoShaftSpeedLimitStatus : 41|3@1+ (1,0) [0|7] "" Vector__XXX
 SG_ FrntPtEnmMdRqstStts : 44|2@1+ (1,0) [0|3] "" Vector__XXX
 SG_ FrontPtoModeRequestStatus : 46|2@1+ (1,0) [0|3] "" Vector__XXX
 SG_ FrontPtoExitReasonCode : 48|6@1+ (1,0) [0|63] "" Vector__XXX

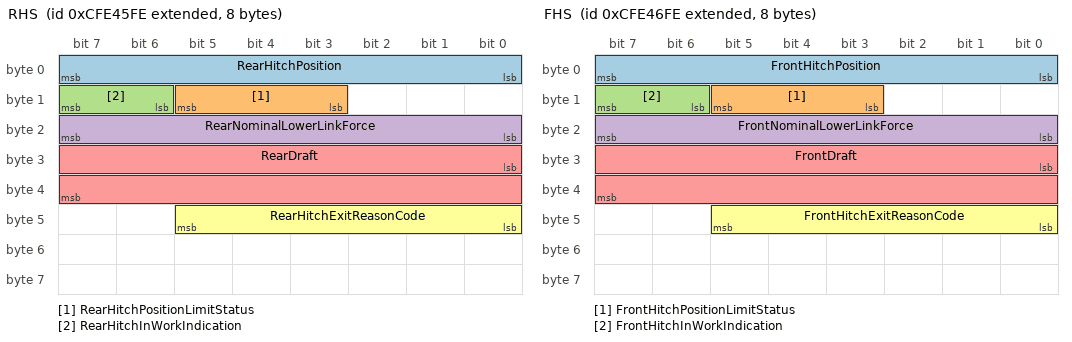
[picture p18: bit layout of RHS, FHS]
BO_ 2365474302 RHS: 8 Vector__XXX
 SG_ RearHitchPosition : 0|8@1+ (0.4,0) [0|100] "%" Vector__XXX
 SG_ RearHitchPositionLimitStatus : 11|3@1+ (1,0) [0|7] "" Vector__XXX
 SG_ RearHitchInWorkIndication : 14|2@1+ (1,0) [0|3] "" Vector__XXX
 SG_ RearNominalLowerLinkForce : 16|8@1+ (0.8,-100) [-100|100] "%" Vector__XXX
 SG_ RearDraft : 24|16@1+ (10,-320000) [-320000|322550] "N" Vector__XXX
 SG_ RearHitchExitReasonCode : 40|6@1+ (1,0) [0|63] "" Vector__XXX

BO_ 2365474558 FHS: 8 Vector__XXX
 SG_ FrontHitchPosition : 0|8@1+ (0.4,0) [0|100] "%" Vector__XXX
 SG_ FrontHitchPositionLimitStatus : 11|3@1+ (1,0) [0|7] "" Vector__XXX
 SG_ FrontHitchInWorkIndication : 14|2@1+ (1,0) [0|3] "" Vector__XXX
 SG_ FrontNominalLowerLinkForce : 16|8@1+ (0.8,-100) [-100|100] "%" Vector__XXX
 SG_ FrontDraft : 24|16@1+ (10,-320000) [-320000|322550] "N" Vector__XXX
 SG_ FrontHitchExitReasonCode : 40|6@1+ (1,0) [0|63] "" Vector__XXX

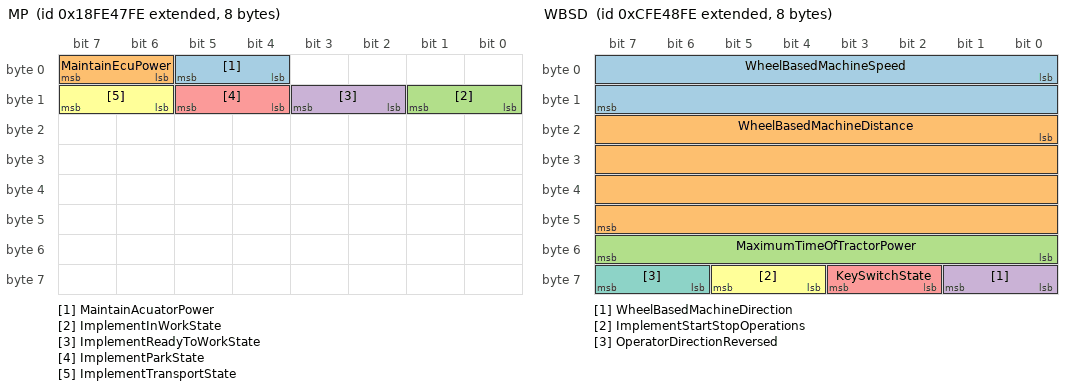
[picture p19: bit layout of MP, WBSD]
BO_ 2566801406 MP: 8 Vector__XXX
 SG_ MaintainAcuatorPower : 4|2@1+ (1,0) [0|3] "" Vector__XXX
 SG_ MaintainEcuPower : 6|2@1+ (1,0) [0|3] "" Vector__XXX
 SG_ ImplementInWorkState : 8|2@1+ (1,0) [0|3] "" Vector__XXX
 SG_ ImplementReadyToWorkState : 10|2@1+ (1,0) [0|3] "" Vector__XXX
 SG_ ImplementParkState : 12|2@1+ (1,0) [0|3] "" Vector__XXX
 SG_ ImplementTransportState : 14|2@1+ (1,0) [0|3] "" Vector__XXX

BO_ 2365475070 WBSD: 8 Vector__XXX
 SG_ WheelBasedMachineSpeed : 0|16@1+ (0.001,0) [0|64.255] "m/s" Vector__XXX
 SG_ WheelBasedMachineDistance : 16|32@1+ (0.001,0) [0|4211081.215] "m" Vector__XXX
 SG_ MaximumTimeOfTractorPower : 48|8@1+ (1,0) [0|250] "min" Vector__XXX
 SG_ WheelBasedMachineDirection : 56|2@1+ (1,0) [0|3] "" Vector__XXX
 SG_ KeySwitchState : 58|2@1+ (1,0) [0|3] "" Vector__XXX
 SG_ ImplementStartStopOperations : 60|2@1+ (1,0) [0|3] "" Vector__XXX
 SG_ OperatorDirectionReversed : 62|2@1+ (1,0) [0|3] "" Vector__XXX

BO_ 2365475326 GBSD: 8 Vector__XXX
 SG_ GroundBasedMachineSpeed : 0|16@1+ (0.001,0) [0|64.255] "m/s" Vector__XXX
 SG_ GroundBasedMachineDistance : 16|32@1+ (0.001,0) [0|4211081.215] "m" Vector__XXX
 SG_ GroundBasedMachineDirection : 56|2@1+ (1,0) [0|3] "" Vector__XXX

CM_ BO_ 2365462014 "Auxiliary valve 5 estimated flow";
CM_ SG_ 2365462014 AxlrVlvNmr05ExtndPrtEstmtdFlw "Auxiliary valve number 05 extend port estimated flow: Value reported by the flow controller through the extend port of auxiliary valve 054 of a tractor, which could be based on the commanded position of the valve. Zero percent indicates no flow, 100 ...";
CM_ SG_ 2365462014 AxlrVlvNmr05RtrtPrtEstmtdFlw "Auxiliary valve number 05 retract port estimated flow: Value reported by the flow controller through the retract port of auxiliary valve 05 of a tractor, which could be based on the commanded position of the valve. Zero percent indicates no flow, 100...";
CM_ SG_ 2365462014 AxlrVlvNmr05VlvStt "Auxiliary valve number 05 valve state: Measured state of the auxiliary valve number 05. A blocked state means that the valve is closed and there is no flow from or to the valve and that the fluid may be under pressure. A floating state means that the...";
CM_ SG_ 2365462014 AuxiliaryValve05FailSafeMode "Auxiliary valve 05 fail safe mode: Measured state of the fail safe mode of auxiliary valve number 05. Value Meaning 00 Block 01 Float 10 Error indication 11 Not available";
CM_ SG_ 2365462014 AxlrVlvNmr05EstmtdFlwLmtStts "Auxiliary valve number 05 estimated flow limit status: This parameter is used to report the Tractor ECU's present estimated flow limit status associated with valve number 05 flow commands that are persistent. Value Meaning 000 Not limited 001 Operato...";
CM_ SG_ 2365462014 AuxiliaryValve05ExitReasonCode "Auxiliary valve 05 exit/reason code: This parameter is used to indicate why the auxiliary valve 05 cannot accept remote commands or has most recently stopped accepting remote commands. Value Meaning 000000 No reason/all clear 000001 Required level of...";
CM_ SG_ 2365462014 AxlrVlv05EstmtdFlwHghRsltn "Auxiliary valve 05 estimated flow (high resolution): Value reported by the controller of flow out of an auxiliary valve 05 of a tractor which could be based on the commanded position of the valve. If this parameter is “not available” (all 1’s) then o...";
CM_ BO_ 2365462270 "Auxiliary valve 6 estimated flow";
CM_ SG_ 2365462270 AxlrVlvNmr06ExtndPrtEstmtdFlw "Auxiliary valve number 06 extend port estimated flow: Value reported by the flow controller through the extend port of auxiliary valve 06 of a tractor, which could be based on the commanded position of the valve. Zero percent indicates no flow, 100 %...";
CM_ SG_ 2365462270 AxlrVlvNmr06RtrtPrtEstmtdFlw "Auxiliary valve number 06 retract port estimated flow: Value reported by the flow controller through the retract port of auxiliary valve 06 of a tractor, which could be based on the commanded position of the valve. Zero percent indicates no flow, 100...";
CM_ SG_ 2365462270 AxlrVlvNmr06VlvStt "Auxiliary valve number 06 valve state: Measured state of the auxiliary valve number 06. A blocked state means that the valve is closed and there is no flow from or to the valve and that the fluid may be under pressure. A floating state means that the...";
CM_ SG_ 2365462270 AuxiliaryValve06FailSafeMode "Auxiliary valve 06 fail safe mode: Measured state of the fail safe mode of auxiliary valve number 06. Value Meaning 00 Block 01 Float 10 Error indication 11 Not available";
CM_ SG_ 2365462270 AxlrVlvNmr06EstmtdFlwLmtStts "Auxiliary valve number 06 estimated flow limit status: This parameter is used to report the Tractor ECU's present estimated flow limit status associated with valve number 06 flow commands that are persistent. Value Meaning 000 Not limited 001 Operato...";
CM_ SG_ 2365462270 AuxiliaryValve06ExitReasonCode "Auxiliary valve 06 exit/reason code: This parameter is used to indicate why the auxiliary valve 06 cannot accept remote commands or has most recently stopped accepting remote commands. Value Meaning 000000 No reason/all clear 000001 Required level of...";
CM_ SG_ 2365462270 AxlrVlv06EstmtdFlwHghRsltn "Auxiliary valve 06 estimated flow (high resolution): Value reported by the controller of flow out of an auxiliary valve 06 of a tractor which could be based on the commanded position of the valve. If this parameter is “not available” (all 1’s) then o...";
CM_ BO_ 2365462526 "Auxiliary valve 7 estimated flow";
CM_ SG_ 2365462526 AxlrVlvNmr07ExtndPrtEstmtdFlw "Auxiliary valve number 07 extend port estimated flow: Value reported by the flow controller through the extend port of auxiliary valve 07 of a tractor, which could be based on the commanded position of the valve. Zero percent indicates no flow, 100 %...";
CM_ SG_ 2365462526 AxlrVlvNmr07RtrtPrtEstmtdFlw "Auxiliary valve number 07 retract port estimated flow: Value reported by the flow controller through the retract port of auxiliary valve 07 of a tractor, which could be based on the commanded position of the valve. Zero percent indicates no flow, 100...";
CM_ SG_ 2365462526 AxlrVlvNmr07VlvStt "Auxiliary valve number 07 valve state: Measured state of the auxiliary valve number 07. A blocked state means that the valve is closed and there is no flow from or to the valve and that the fluid may be under pressure. A floating state means that the...";
CM_ SG_ 2365462526 AuxiliaryValve07FailSafeMode "Auxiliary valve 07 fail safe mode: Measured state of the fail safe mode of auxiliary valve number 07. Value Meaning 00 Block 01 Float 10 Error indication 11 Not available";
CM_ SG_ 2365462526 AxlrVlvNmr07EstmtdFlwLmtStts "Auxiliary valve number 07 estimated flow limit status: This parameter is used to report the Tractor ECU's present estimated flow limit status associated with valve number 07 flow commands that are persistent. Value Meaning 000 Not limited 001 Operato...";
CM_ SG_ 2365462526 AuxiliaryValve07ExitReasonCode "Auxiliary valve 07 exit/reason code: This parameter is used to indicate why the auxiliary valve 07 cannot accept remote commands or has most recently stopped accepting remote commands. Value Meaning 000000 No reason/all clear 000001 Required level of...";
CM_ SG_ 2365462526 AxlrVlv07EstmtdFlwHghRsltn "Auxiliary valve 07 estimated flow (high resolution): Value reported by the controller of flow out of an auxiliary valve 07 of a tractor which could be based on the commanded position of the valve. If this parameter is “not available” (all 1’s) then o...";
CM_ BO_ 2365462782 "Auxiliary valve 8 estimated flow";
CM_ SG_ 2365462782 AxlrVlvNmr08ExtndPrtEstmtdFlw "Auxiliary valve number 08 extend port estimated flow: Value reported by the flow controller through the extend port of auxiliary valve 08 of a tractor, which could be based on the commanded position of the valve. Zero percent indicates no flow, 100 %...";
CM_ SG_ 2365462782 AxlrVlvNmr08RtrtPrtEstmtdFlw "Auxiliary valve number 08 retract port estimated flow: Value reported by the flow controller through the retract port of auxiliary valve 08 of a tractor, which could be based on the commanded position of the valve. Zero percent indicates no flow, 100...";
CM_ SG_ 2365462782 AxlrVlvNmr08VlvStt "Auxiliary valve number 08 valve state: Measured state of the auxiliary valve number 08. A blocked state means that the valve is closed and there is no flow from or to the valve and that the fluid may be under pressure. A floating state means that the...";
CM_ SG_ 2365462782 AuxiliaryValve08FailSafeMode "Auxiliary valve 08 fail safe mode: Measured state of the fail safe mode of auxiliary valve number 08. Value Meaning 00 Block 01 Float 10 Error indication 11 Not available";
CM_ SG_ 2365462782 AxlrVlvNmr08EstmtdFlwLmtStts "Auxiliary valve number 08 estimated flow limit status: This parameter is used to report the Tractor ECU's present estimated flow limit status associated with valve number 08 flow commands that are persistent. Value Meaning 000 Not limited 001 Operato...";
CM_ SG_ 2365462782 AuxiliaryValve08ExitReasonCode "Auxiliary valve 08 exit/reason code: This parameter is used to indicate why the auxiliary valve 08 cannot accept remote commands or has most recently stopped accepting remote commands. Value Meaning 000000 No reason/all clear 000001 Required level of...";
CM_ SG_ 2365462782 AxlrVlv08EstmtdFlwHghRsltn "Auxiliary valve 08 estimated flow (high resolution): Value reported by the controller of flow out of an auxiliary valve 08 of a tractor which could be based on the commanded position of the valve. If this parameter is “not available” (all 1’s) then o...";
CM_ BO_ 2365463038 "Auxiliary valve 9 estimated flow";
CM_ SG_ 2365463038 AxlrVlvNmr09ExtndPrtEstmtdFlw "Auxiliary valve number 09 extend port estimated flow: Value reported by the flow controller through the extend port of auxiliary valve 09 of a tractor, which could be based on the commanded position of the valve. Zero percent indicates no flow, 100 %...";
CM_ SG_ 2365463038 AxlrVlvNmr09RtrtPrtEstmtdFlw "Auxiliary valve number 09 retract port estimated flow: Value reported by the flow controller through the retract port of auxiliary valve 09 of a tractor, which could be based on the commanded position of the valve. Zero percent indicates no flow, 100...";
CM_ SG_ 2365463038 AxlrVlvNmr09VlvStt "Auxiliary valve number 09 valve state: Measured state of the auxiliary valve number 09. A blocked state means that the valve is closed and there is no flow from or to the valve and that the fluid may be under pressure. A floating state means that the...";
CM_ SG_ 2365463038 AuxiliaryValve09FailSafeMode "Auxiliary valve 09 fail safe mode: Measured state of the fail safe mode of auxiliary valve number 09. Value Meaning 00 Block 01 Float 10 Error indication 11 Not available";
CM_ SG_ 2365463038 AxlrVlvNmr09EstmtdFlwLmtStts "Auxiliary valve number 09 estimated flow limit status: This parameter is used to report the Tractor ECU's present estimated flow limit status associated with valve number 09 flow commands that are persistent. Value Meaning 000 Not limited 001 Operato...";
CM_ SG_ 2365463038 AuxiliaryValve09ExitReasonCode "Auxiliary valve 09 exit/reason code: This parameter is used to indicate why the auxiliary valve 09 cannot accept remote commands or has most recently stopped accepting remote commands. Value Meaning 000000 No reason/all clear 000001 Required level of...";
CM_ SG_ 2365463038 AxlrVlv09EstmtdFlwHghRsltn "Auxiliary valve 09 estimated flow (high resolution): Value reported by the controller of flow out of an auxiliary valve 09 of a tractor which could be based on the commanded position of the valve. If this parameter is “not available” (all 1’s) then o...";
CM_ BO_ 2365463294 "Auxiliary valve 10 estimated flow";
CM_ SG_ 2365463294 AxlrVlvNmr10ExtndPrtEstmtdFlw "Auxiliary valve number 10 extend port estimated flow: Value reported by the flow controller through the extend port of auxiliary valve 10 of a tractor, which could be based on the commanded position of the valve. Zero percent indicates no flow, 100 %...";
CM_ SG_ 2365463294 AxlrVlvNmr10RtrtPrtEstmtdFlw "Auxiliary valve number 10 retract port estimated flow: Value reported by the flow controller through the retract port of auxiliary valve 10 of a tractor, which could be based on the commanded position of the valve. Zero percent indicates no flow, 100...";
CM_ SG_ 2365463294 AxlrVlvNmr10VlvStt "Auxiliary valve number 10 valve state: Measured state of the auxiliary valve number 10. A blocked state means that the valve is closed and there is no flow from or to the valve and that the fluid may be under pressure. A floating state means that the...";
CM_ SG_ 2365463294 AuxiliaryValve10FailSafeMode "Auxiliary valve 10 fail safe mode: Measured state of the fail safe mode of auxiliary valve number 10. Value Meaning 00 Block 01 Float 10 Error indication 11 Not available";
CM_ SG_ 2365463294 AxlrVlvNmr10EstmtdFlwLmtStts "Auxiliary valve number 10 estimated flow limit status: This parameter is used to report the Tractor ECU's present estimated flow limit status associated with valve number 10 flow commands that are persistent. Value Meaning 000 Not limited 001 Operato...";
CM_ SG_ 2365463294 AuxiliaryValve10ExitReasonCode "Auxiliary valve 10 exit/reason code: This parameter is used to indicate why the auxiliary valve 10 cannot accept remote commands or has most recently stopped accepting remote commands. Value Meaning 000000 No reason/all clear 000001 Required level of...";
CM_ SG_ 2365463294 AxlrVlv10EstmtdFlwHghRsltn "Auxiliary valve 10 estimated flow (high resolution): Value reported by the controller of flow out of an auxiliary valve 10 of a tractor which could be based on the commanded position of the valve. If this parameter is “not available” (all 1’s) then o...";
CM_ BO_ 2365463550 "Auxiliary valve 11 estimated flow";
CM_ SG_ 2365463550 AxlrVlvNmr11ExtndPrtEstmtdFlw "Auxiliary valve number 11 extend port estimated flow: Value reported by the flow controller through the extend port of auxiliary valve 11 of a tractor, which could be based on the commanded position of the valve. Zero percent indicates no flow, 100 %...";
CM_ SG_ 2365463550 AxlrVlvNmr11RtrtPrtEstmtdFlw "Auxiliary valve number 11 retract port estimated flow: Value reported by the flow controller through the retract port of auxiliary valve 11 of a tractor, which could be based on the commanded position of the valve. Zero percent indicates no flow, 100...";
CM_ SG_ 2365463550 AxlrVlvNmr11VlvStt "Auxiliary valve number 11 valve state: Measured state of the auxiliary valve number 11. A blocked state means that the valve is closed and there is no flow from or to the valve and that the fluid may be under pressure. A floating state means that the...";
CM_ SG_ 2365463550 AuxiliaryValve11FailSafeMode "Auxiliary valve 11 fail safe mode: Measured state of the fail safe mode of auxiliary valve number 11. Value Meaning 00 Block 01 Float 10 Error indication 11 Not available";
CM_ SG_ 2365463550 AxlrVlvNmr11EstmtdFlwLmtStts "Auxiliary valve number 11 estimated flow limit status: This parameter is used to report the Tractor ECU's present estimated flow limit status associated with valve number 11 flow commands that are persistent. Value Meaning 000 Not limited 001 Operato...";
CM_ SG_ 2365463550 AuxiliaryValve11ExitReasonCode "Auxiliary valve 11 exit/reason code: This parameter is used to indicate why the auxiliary valve 11 cannot accept remote commands or has most recently stopped accepting remote commands. Value Meaning 000000 No reason/all clear 000001 Required level of...";
CM_ SG_ 2365463550 AxlrVlv11EstmtdFlwHghRsltn "Auxiliary valve 11 estimated flow (high resolution): Value reported by the controller of flow out of an auxiliary valve 11 of a tractor which could be based on the commanded position of the valve. If this parameter is “not available” (all 1’s) then o...";
CM_ BO_ 2365463806 "Auxiliary valve 12 estimated flow";
CM_ SG_ 2365463806 AxlrVlvNmr12ExtndPrtEstmtdFlw "Auxiliary valve number 12 extend port estimated flow: Value reported by the flow controller through the extend port of auxiliary valve 12 of a tractor, which could be based on the commanded position of the valve. Zero percent indicates no flow, 100 %...";
CM_ SG_ 2365463806 AxlrVlvNmr12RtrtPrtEstmtdFlw "Auxiliary valve number 12 retract port estimated flow: Value reported by the flow controller through the retract port of auxiliary valve 12 of a tractor, which could be based on the commanded position of the valve. Zero percent indicates no flow, 100...";
CM_ SG_ 2365463806 AxlrVlvNmr12VlvStt "Auxiliary valve number 12 valve state: Measured state of the auxiliary valve number 12. A blocked state means that the valve is closed and there is no flow from or to the valve and that the fluid may be under pressure. A floating state means that the...";
CM_ SG_ 2365463806 AuxiliaryValve12FailSafeMode "Auxiliary valve 12 fail safe mode: Measured state of the fail safe mode of auxiliary valve number 12. Value Meaning 00 Block 01 Float 10 Error indication 11 Not available";
CM_ SG_ 2365463806 AxlrVlvNmr12EstmtdFlwLmtStts "Auxiliary valve number 12 estimated flow limit status: This parameter is used to report the Tractor ECU's present estimated flow limit status associated with valve number 12 flow commands that are persistent. Value Meaning 000 Not limited 001 Operato...";
CM_ SG_ 2365463806 AuxiliaryValve12ExitReasonCode "Auxiliary valve 12 exit/reason code: This parameter is used to indicate why the auxiliary valve 12 cannot accept remote commands or has most recently stopped accepting remote commands. Value Meaning 000000 No reason/all clear 000001 Required level of...";
CM_ SG_ 2365463806 AxlrVlv12EstmtdFlwHghRsltn "Auxiliary valve 12 estimated flow (high resolution): Value reported by the controller of flow out of an auxiliary valve 12 of a tractor which could be based on the commanded position of the valve. If this parameter is “not available” (all 1’s) then o...";
CM_ BO_ 2365464062 "Auxiliary valve 13 estimated flow";
CM_ SG_ 2365464062 AxlrVlvNmr13ExtndPrtEstmtdFlw "Auxiliary valve number 13 extend port estimated flow: Value reported by the flow controller through the extend port of auxiliary valve 13 of a tractor, which could be based on the commanded position of the valve. Zero percent indicates no flow, 100 %...";
CM_ SG_ 2365464062 AxlrVlvNmr13RtrtPrtEstmtdFlw "Auxiliary valve number 13 retract port estimated flow: Value reported by the flow controller through the retract port of auxiliary valve 13 of a tractor, which could be based on the commanded position of the valve. Zero percent indicates no flow, 100...";
CM_ SG_ 2365464062 AxlrVlvNmr13VlvStt "Auxiliary valve number 13 valve state: Measured state of the auxiliary valve number 13. A blocked state means that the valve is closed and there is no flow from or to the valve and that the fluid may be under pressure. A floating state means that the...";
CM_ SG_ 2365464062 AuxiliaryValve13FailSafeMode "Auxiliary valve 13 fail safe mode: Measured state of the fail safe mode of auxiliary valve number 13. Value Meaning 00 Block 01 Float 10 Error indication 11 Not available";
CM_ SG_ 2365464062 AxlrVlvNmr13EstmtdFlwLmtStts "Auxiliary valve number 13 estimated flow limit status: This parameter is used to report the Tractor ECU's present estimated flow limit status associated with valve number 13 flow commands that are persistent. Value Meaning 000 Not limited 001 Operato...";
CM_ SG_ 2365464062 AuxiliaryValve13ExitReasonCode "Auxiliary valve 13 exit/reason code: This parameter is used to indicate why the auxiliary valve 13 cannot accept remote commands or has most recently stopped accepting remote commands. Value Meaning 000000 No reason/all clear 000001 Required level of...";
CM_ SG_ 2365464062 AxlrVlv13EstmtdFlwHghRsltn "Auxiliary valve 13 estimated flow (high resolution): Value reported by the controller of flow out of an auxiliary valve 13 of a tractor which could be based on the commanded position of the valve. If this parameter is “not available” (all 1’s) then o...";
CM_ BO_ 2365464318 "Auxiliary valve 14 estimated flow";
CM_ SG_ 2365464318 AxlrVlvNmr14ExtndPrtEstmtdFlw "Auxiliary valve number 14 extend port estimated flow: Value reported by the flow controller through the extend port of auxiliary valve 14 of a tractor, which could be based on the commanded position of the valve. Zero percent indicates no flow, 100 %...";
CM_ SG_ 2365464318 AxlrVlvNmr14RtrtPrtEstmtdFlw "Auxiliary valve number 14 retract port estimated flow: Value reported by the flow controller through the retract port of auxiliary valve 14 of a tractor, which could be based on the commanded position of the valve. Zero percent indicates no flow, 100...";
CM_ SG_ 2365464318 AxlrVlvNmr14VlvStt "Auxiliary valve number 14 valve state: Measured state of the auxiliary valve number 14. A blocked state means that the valve is closed and there is no flow from or to the valve and that the fluid may be under pressure. A floating state means that the...";
CM_ SG_ 2365464318 AuxiliaryValve14FailSafeMode "Auxiliary valve 14 fail safe mode: Measured state of the fail safe mode of auxiliary valve number 14. Value Meaning 00 Block 01 Float 10 Error indication 11 Not available";
CM_ SG_ 2365464318 AxlrVlvNmr14EstmtdFlwLmtStts "Auxiliary valve number 14 estimated flow limit status: This parameter is used to report the Tractor ECU's present estimated flow limit status associated with valve number 14 flow commands that are persistent. Value Meaning 000 Not limited 001 Operato...";
CM_ SG_ 2365464318 AuxiliaryValve14ExitReasonCode "Auxiliary valve 14 exit/reason code: This parameter is used to indicate why the auxiliary valve 14 cannot accept remote commands or has most recently stopped accepting remote commands. Value Meaning 000000 No reason/all clear 000001 Required level of...";
CM_ SG_ 2365464318 AxlrVlv14EstmtdFlwHghRsltn "Auxiliary valve 14 estimated flow (high resolution): Value reported by the controller of flow out of an auxiliary valve 14 of a tractor which could be based on the commanded position of the valve. If this parameter is “not available” (all 1’s) then o...";
CM_ BO_ 2365464574 "Auxiliary valve 15 estimated flow";
CM_ SG_ 2365464574 AxlrVlvNmr15ExtndPrtEstmtdFlw "Auxiliary valve number 15 extend port estimated flow: Value reported by the flow controller through the extend port of auxiliary valve 15 of a tractor, which could be based on the commanded position of the valve. Zero percent indicates no flow, 100 %...";
CM_ SG_ 2365464574 AxlrVlvNmr15RtrtPrtEstmtdFlw "Auxiliary valve number 15 retract port estimated flow: Value reported by the flow controller through the retract port of auxiliary valve 15 of a tractor, which could be based on the commanded position of the valve. Zero percent indicates no flow, 100...";
CM_ SG_ 2365464574 AxlrVlvNmr15VlvStt "Auxiliary valve number 15 valve state: Measured state of the auxiliary valve number 15. A blocked state means that the valve is closed and there is no flow from or to the valve and that the fluid may be under pressure. A floating state means that the...";
CM_ SG_ 2365464574 AuxiliaryValve15FailSafeMode "Auxiliary valve 15 fail safe mode: Measured state of the fail safe mode of auxiliary valve number 15. Value Meaning 00 Block 01 Float 10 Error indication 11 Not available";
CM_ SG_ 2365464574 AxlrVlvNmr15EstmtdFlwLmtStts "Auxiliary valve number 15 estimated flow limit status: This parameter is used to report the Tractor ECU's present estimated flow limit status associated with valve number 15 flow commands that are persistent. Value Meaning 000 Not limited 001 Operato...";
CM_ SG_ 2365464574 AuxiliaryValve15ExitReasonCode "Auxiliary valve 15 exit/reason code: This parameter is used to indicate why the auxiliary valve 15 cannot accept remote commands or has most recently stopped accepting remote commands. Value Meaning 000000 No reason/all clear 000001 Required level of...";
CM_ SG_ 2365464574 AxlrVlv15EstmtdFlwHghRsltn "Auxiliary valve 15 estimated flow (high resolution): Value reported by the controller of flow out of an auxiliary valve 15 of a tractor which could be based on the commanded position of the valve. If this parameter is “not available” (all 1’s) then o...";
CM_ BO_ 2365464830 "Auxiliary valve 0 measured flow";
CM_ SG_ 2365464830 AxlrVlvNmr0ExtndPrtMsrdFlw "Auxiliary valve number 0 extend port measured flow: Measured flow through the extend port of auxiliary valve number 0 of a tractor, expressed as a percentage of full flow. Zero percent indicates no flow, 100 % indicates maximum flow, −100 % indicates...";
CM_ SG_ 2365464830 AxlrVlvNmr0RtrtPrtMsrdFlw "Auxiliary valve number 0 retract port measured flow: Measured flow through the retract port of auxiliary valve number 0 of a tractor, expressed as a percentage of full flow. Zero percent indicates no flow, 100 % indicates maximum flow, −100 % indicat...";
CM_ SG_ 2365464830 AxlrVlvNmr0RtrnPrtPrssr "Auxiliary valve number 0 return port pressure: Measured nominal pressure at the return port of auxiliary valve 0 of a tractor.";
CM_ SG_ 2365464830 AxlrVlvNmr0ExtndPrtPrssr "Auxiliary valve number 0 extend port pressure: Measured nominal pressure at the extend port of auxiliary valve 0 of a tractor.";
CM_ SG_ 2365464830 AxlrVlv0RtrtPrtPrssr "Auxiliary valve 0 retract port pressure: Measured nominal pressure at the retract port of auxiliary valve 0 of a tractor.";
CM_ SG_ 2365464830 AxlrVlvNmr0MsrdFlwLmtStts "Auxiliary valve number 0 measured flow limit status: This parameter is used to report the Tractor ECU's present measured flow limit status associated with valve number 0 flow commands that are persistent. Value Meaning 000 Not limited 001 Operator li...";
CM_ BO_ 2365465086 "Auxiliary valve 1 measured flow";
CM_ SG_ 2365465086 AxlrVlvNmr01ExtndPrtMsrdFlw "Auxiliary valve number 01 extend port measured flow: Measured flow through the extend port of auxiliary valve number 15 of a tractor, expressed as a percentage of full flow. Zero percent indicates no flow, 100 % indicates maximum flow, −100 % indicat...";
CM_ SG_ 2365465086 AxlrVlvNmr01RtrtPrtMsrdFlw "Auxiliary valve number 01 retract port measured flow: Measured flow through the retract port of auxiliary valve number 01 of a tractor, expressed as a percentage of full flow. Zero percent indicates no flow, 100 % indicates maximum flow, −100 % indic...";
CM_ SG_ 2365465086 AxlrVlvNmr01RtrnPrtPrssr "Auxiliary valve number 01 return port pressure: Measured nominal pressure at the return port of auxiliary valve 01 of a tractor.";
CM_ SG_ 2365465086 AxlrVlvNmr01ExtndPrtPrssr "Auxiliary valve number 01 extend port pressure: Measured nominal pressure at the extend port of auxiliary valve 01 of a tractor.";
CM_ SG_ 2365465086 AxlrVlvNmr01RtrtPrtPrssr "Auxiliary valve number 01 retract port pressure: Measured nominal pressure at the retract port of auxiliary valve 01 of a tractor.";
CM_ SG_ 2365465086 AxlrVlvNmr01MsrdFlwLmtStts "Auxiliary valve number 01 measured flow limit status: This parameter is used to report the Tractor ECU's present measured flow limit status associated with valve number 01 flow commands that are persistent. Value Meaning 000 Not limited 001 Operator ...";
CM_ BO_ 2365465342 "Auxiliary valve 2 measured flow";
CM_ SG_ 2365465342 AxlrVlvNmr02ExtndPrtMsrdFlw "Auxiliary valve number 02 extend port measured flow: Measured flow through the extend port of auxiliary valve number 02 of a tractor, expressed as a percentage of full flow. Zero percent indicates no flow, 100 % indicates maximum flow, −100 % indicat...";
CM_ SG_ 2365465342 AxlrVlvNmr02RtrtPrtMsrdFlw "Auxiliary valve number 02 retract port measured flow: Measured flow through the retract port of auxiliary valve number 02 of a tractor, expressed as a percentage of full flow. Zero percent indicates no flow, 100 % indicates maximum flow, −100 % indic...";
CM_ SG_ 2365465342 AxlrVlvNmr02RtrnPrtPrssr "Auxiliary valve number 02 return port pressure: Measured nominal pressure at the return port of auxiliary valve 02 of a tractor.";
CM_ SG_ 2365465342 AxlrVlvNmr02ExtndPrtPrssr "Auxiliary valve number 02 extend port pressure: Measured nominal pressure at the extend port of auxiliary valve 02 of a tractor.";
CM_ SG_ 2365465342 AxlrVlvNmr02RtrtPrtPrssr "Auxiliary valve number 02 retract port pressure: Measured nominal pressure at the retract port of auxiliary valve 02 of a tractor.";
CM_ SG_ 2365465342 AxlrVlvNmr02MsrdFlwLmtStts "Auxiliary valve number 02 measured flow limit status: This parameter is used to report the Tractor ECU's present measured flow limit status associated with valve number 02 flow commands that are persistent. Value Meaning 000 Not limited 001 Operator ...";
CM_ BO_ 2365465598 "Auxiliary valve 3 measured flow";
CM_ SG_ 2365465598 AxlrVlvNmr03ExtndPrtMsrdFlw "Auxiliary valve number 03 extend port measured flow: Measured flow through the extend port of auxiliary valve number 03 of a tractor, expressed as a percentage of full flow. Zero percent indicates no flow, 100 % indicates maximum flow, −100 % indicat...";
CM_ SG_ 2365465598 AxlrVlvNmr03RtrtPrtMsrdFlw "Auxiliary valve number 03 retract port measured flow: Measured flow through the retract port of auxiliary valve number 03 of a tractor, expressed as a percentage of full flow. Zero percent indicates no flow, 100 % indicates maximum flow, −100 % indic...";
CM_ SG_ 2365465598 AxlrVlvNmr03RtrnPrtPrssr "Auxiliary valve number 03 return port pressure: Measured nominal pressure at the return port of auxiliary valve 03 of a tractor.";
CM_ SG_ 2365465598 AxlrVlvNmr03ExtndPrtPrssr "Auxiliary valve number 03 extend port pressure: Measured nominal pressure at the extend port of auxiliary valve 03 of a tractor.";
CM_ SG_ 2365465598 AxlrVlvNmr03RtrtPrtPrssr "Auxiliary valve number 03 retract port pressure: Measured nominal pressure at the retract port of auxiliary valve 03 of a tractor.";
CM_ SG_ 2365465598 AxlrVlvNmr03MsrdFlwLmtStts "Auxiliary valve number 03 measured flow limit status: This parameter is used to report the Tractor ECU's present measured flow limit status associated with valve number 03 flow commands that are persistent. Value Meaning 000 Not limited 001 Operator ...";
CM_ BO_ 2365465854 "Auxiliary valve 4 measured flow";
CM_ SG_ 2365465854 AxlrVlvNmr04ExtndPrtMsrdFlw "Auxiliary valve number 04 extend port measured flow: Measured flow through the extend port of auxiliary valve number 04 of a tractor, expressed as a percentage of full flow. Zero percent indicates no flow, 100 % indicates maximum flow, −100 % indicat...";
CM_ SG_ 2365465854 AxlrVlvNmr04RtrtPrtMsrdFlw "Auxiliary valve number 04 retract port measured flow: Measured flow through the retract port of auxiliary valve number 04 of a tractor, expressed as a percentage of full flow. Zero percent indicates no flow, 100 % indicates maximum flow, −100 % indic...";
CM_ SG_ 2365465854 AxlrVlvNmr04RtrnPrtPrssr "Auxiliary valve number 04 return port pressure: Measured nominal pressure at the return port of auxiliary valve 04 of a tractor.";
CM_ SG_ 2365465854 AxlrVlvNmr04ExtndPrtPrssr "Auxiliary valve number 04 extend port pressure: Measured nominal pressure at the extend port of auxiliary valve 04 of a tractor.";
CM_ SG_ 2365465854 AxlrVlvNmr04RtrtPrtPrssr "Auxiliary valve number 04 retract port pressure: Measured nominal pressure at the retract port of auxiliary valve 04 of a tractor.";
CM_ SG_ 2365465854 AxlrVlvNmr04MsrdFlwLmtStts "Auxiliary valve number 04 measured flow limit status: This parameter is used to report the Tractor ECU's present measured flow limit status associated with valve number 04 flow commands that are persistent. Value Meaning 000 Not limited 001 Operator ...";
CM_ BO_ 2365466110 "Auxiliary valve 5 measured flow";
CM_ SG_ 2365466110 AxlrVlvNmr05ExtndPrtMsrdFlw "Auxiliary valve number 05 extend port measured flow: Measured flow through the extend port of auxiliary valve number 05 of a tractor, expressed as a percentage of full flow. Zero percent indicates no flow, 100 % indicates maximum flow, −100 % indicat...";
CM_ SG_ 2365466110 AxlrVlvNmr05RtrtPrtMsrdFlw "Auxiliary valve number 05 retract port measured flow: Measured flow through the retract port of auxiliary valve number 05 of a tractor, expressed as a percentage of full flow. Zero percent indicates no flow, 100 % indicates maximum flow, −100 % indic...";
CM_ SG_ 2365466110 AxlrVlvNmr05RtrnPrtPrssr "Auxiliary valve number 05 return port pressure: Measured nominal pressure at the return port of auxiliary valve 05 of a tractor.";
CM_ SG_ 2365466110 AxlrVlvNmr05ExtndPrtPrssr "Auxiliary valve number 05 extend port pressure: Measured nominal pressure at the extend port of auxiliary valve 05 of a tractor.";
CM_ SG_ 2365466110 AxlrVlvNmr05RtrtPrtPrssr "Auxiliary valve number 05 retract port pressure: Measured nominal pressure at the retract port of auxiliary valve 05 of a tractor.";
CM_ SG_ 2365466110 AxlrVlvNmr05MsrdFlwLmtStts "Auxiliary valve number 05 measured flow limit status: This parameter is used to report the Tractor ECU's present measured flow limit status associated with valve number 05 flow commands that are persistent. Value Meaning 000 Not limited 001 Operator ...";
CM_ BO_ 2365466366 "Auxiliary valve 6 measured flow";
CM_ SG_ 2365466366 AxlrVlvNmr06ExtndPrtMsrdFlw "Auxiliary valve number 06 extend port measured flow: Measured flow through the extend port of auxiliary valve number 06 of a tractor, expressed as a percentage of full flow. Zero percent indicates no flow, 100 % indicates maximum flow, −100 % indicat...";
CM_ SG_ 2365466366 AxlrVlvNmr06RtrtPrtMsrdFlw "Auxiliary valve number 06 retract port measured flow: Measured flow through the retract port of auxiliary valve number 06 of a tractor, expressed as a percentage of full flow. Zero percent indicates no flow, 100 % indicates maximum flow, −100 % indic...";
CM_ SG_ 2365466366 AxlrVlvNmr06RtrnPrtPrssr "Auxiliary valve number 06 return port pressure: Measured nominal pressure at the return port of auxiliary valve 06 of a tractor.";
CM_ SG_ 2365466366 AxlrVlvNmr06ExtndPrtPrssr "Auxiliary valve number 06 extend port pressure: Measured nominal pressure at the extend port of auxiliary valve 06 of a tractor.";
CM_ SG_ 2365466366 AxlrVlvNmr06RtrtPrtPrssr "Auxiliary valve number 06 retract port pressure: Measured nominal pressure at the retract port of auxiliary valve 06 of a tractor.";
CM_ SG_ 2365466366 AxlrVlvNmr06MsrdFlwLmtStts "Auxiliary valve number 06 measured flow limit status: This parameter is used to report the Tractor ECU's present measured flow limit status associated with valve number 06 flow commands that are persistent. Value Meaning 000 Not limited 001 Operator ...";
CM_ BO_ 2365466622 "Auxiliary valve 7 measured flow";
CM_ SG_ 2365466622 AxlrVlvNmr07ExtndPrtMsrdFlw "Auxiliary valve number 07 extend port measured flow: Measured flow through the extend port of auxiliary valve number 07 of a tractor, expressed as a percentage of full flow. Zero percent indicates no flow, 100 % indicates maximum flow, −100 % indicat...";
CM_ SG_ 2365466622 AxlrVlvNmr07RtrtPrtMsrdFlw "Auxiliary valve number 07 retract port measured flow: Measured flow through the retract port of auxiliary valve number 07 of a tractor, expressed as a percentage of full flow. Zero percent indicates no flow, 100 % indicates maximum flow, −100 % indic...";
CM_ SG_ 2365466622 AxlrVlvNmr07RtrnPrtPrssr "Auxiliary valve number 07 return port pressure: Measured nominal pressure at the return port of auxiliary valve 07 of a tractor.";
CM_ SG_ 2365466622 AxlrVlvNmr07ExtndPrtPrssr "Auxiliary valve number 07 extend port pressure: Measured nominal pressure at the extend port of auxiliary valve 07 of a tractor.";
CM_ SG_ 2365466622 AxlrVlvNmr07RtrtPrtPrssr "Auxiliary valve number 07 retract port pressure: Measured nominal pressure at the retract port of auxiliary valve 07 of a tractor.";
CM_ SG_ 2365466622 AxlrVlvNmr07MsrdFlwLmtStts "Auxiliary valve number 07 measured flow limit status: This parameter is used to report the Tractor ECU's present measured flow limit status associated with valve number 07 flow commands that are persistent. Value Meaning 000 Not limited 001 Operator ...";
CM_ BO_ 2365466878 "Auxiliary valve 8 measured flow";
CM_ SG_ 2365466878 AxlrVlvNmr08ExtndPrtMsrdFlw "Auxiliary valve number 08 extend port measured flow: Measured flow through the extend port of auxiliary valve number 08 of a tractor, expressed as a percentage of full flow. Zero percent indicates no flow, 100 % indicates maximum flow, −100 % indicat...";
CM_ SG_ 2365466878 AxlrVlvNmr08RtrtPrtMsrdFlw "Auxiliary valve number 08 retract port measured flow: Measured flow through the retract port of auxiliary valve number 08 of a tractor, expressed as a percentage of full flow. Zero percent indicates no flow, 100 % indicates maximum flow, −100 % indic...";
CM_ SG_ 2365466878 AxlrVlvNmr08RtrnPrtPrssr "Auxiliary valve number 08 return port pressure: Measured nominal pressure at the return port of auxiliary valve 08 of a tractor.";
CM_ SG_ 2365466878 AxlrVlvNmr08ExtndPrtPrssr "Auxiliary valve number 08 extend port pressure: Measured nominal pressure at the extend port of auxiliary valve 08 of a tractor.";
CM_ SG_ 2365466878 AxlrVlvNmr08RtrtPrtPrssr "Auxiliary valve number 08 retract port pressure: Measured nominal pressure at the retract port of auxiliary valve 08 of a tractor.";
CM_ SG_ 2365466878 AxlrVlvNmr08MsrdFlwLmtStts "Auxiliary valve number 08 measured flow limit status: This parameter is used to report the Tractor ECU's present measured flow limit status associated with valve number 08 flow commands that are persistent. Value Meaning 000 Not limited 001 Operator ...";
CM_ BO_ 2365467134 "Auxiliary valve 9 measured flow";
CM_ SG_ 2365467134 AxlrVlvNmr09ExtndPrtMsrdFlw "Auxiliary valve number 09 extend port measured flow: Measured flow through the extend port of auxiliary valve number 09 of a tractor, expressed as a percentage of full flow. Zero percent indicates no flow, 100 % indicates maximum flow, −100 % indicat...";
CM_ SG_ 2365467134 AxlrVlvNmr09RtrtPrtMsrdFlw "Auxiliary valve number 09 retract port measured flow: Measured flow through the retract port of auxiliary valve number 09 of a tractor, expressed as a percentage of full flow. Zero percent indicates no flow, 100 % indicates maximum flow, −100 % indic...";
CM_ SG_ 2365467134 AxlrVlvNmr09RtrnPrtPrssr "Auxiliary valve number 09 return port pressure: Measured nominal pressure at the return port of auxiliary valve 09 of a tractor.";
CM_ SG_ 2365467134 AxlrVlvNmr09ExtndPrtPrssr "Auxiliary valve number 09 extend port pressure: Measured nominal pressure at the extend port of auxiliary valve 09 of a tractor.";
CM_ SG_ 2365467134 AxlrVlvNmr09RtrtPrtPrssr "Auxiliary valve number 09 retract port pressure: Measured nominal pressure at the retract port of auxiliary valve 09 of a tractor.";
CM_ SG_ 2365467134 AxlrVlvNmr09MsrdFlwLmtStts "Auxiliary valve number 09 measured flow limit status: This parameter is used to report the Tractor ECU's present measured flow limit status associated with valve number 09 flow commands that are persistent. Value Meaning 000 Not limited 001 Operator ...";
CM_ BO_ 2365467390 "Auxiliary valve 10 measured flow";
CM_ SG_ 2365467390 AxlrVlvNmr10ExtndPrtMsrdFlw "Auxiliary valve number 10 extend port measured flow: Measured flow through the extend port of auxiliary valve number 10 of a tractor, expressed as a percentage of full flow. Zero percent indicates no flow, 100 % indicates maximum flow, −100 % indicat...";
CM_ SG_ 2365467390 AxlrVlvNmr10RtrtPrtMsrdFlw "Auxiliary valve number 10 retract port measured flow: Measured flow through the retract port of auxiliary valve number 10 of a tractor, expressed as a percentage of full flow. Zero percent indicates no flow, 100 % indicates maximum flow, −100 % indic...";
CM_ SG_ 2365467390 AxlrVlvNmr10RtrnPrtPrssr "Auxiliary valve number 10 return port pressure: Measured nominal pressure at the return port of auxiliary valve 10 of a tractor.";
CM_ SG_ 2365467390 AxlrVlvNmr10ExtndPrtPrssr "Auxiliary valve number 10 extend port pressure: Measured nominal pressure at the extend port of auxiliary valve 10 of a tractor.";
CM_ SG_ 2365467390 AxlrVlvNmr10RtrtPrtPrssr "Auxiliary valve number 10 retract port pressure: Measured nominal pressure at the retract port of auxiliary valve 10 of a tractor.";
CM_ SG_ 2365467390 AxlrVlvNmr10MsrdFlwLmtStts "Auxiliary valve number 10 measured flow limit status: This parameter is used to report the Tractor ECU's present measured flow limit status associated with valve number 10 flow commands that are persistent. Value Meaning 000 Not limited 001 Operator ...";
CM_ BO_ 2365467646 "Auxiliary valve 11 measured flow";
CM_ SG_ 2365467646 AxlrVlvNmr11ExtndPrtMsrdFlw "Auxiliary valve number 11 extend port measured flow: Measured flow through the extend port of auxiliary valve number 10 of a tractor, expressed as a percentage of full flow. Zero percent indicates no flow, 100 % indicates maximum flow, −100 % indicat...";
CM_ SG_ 2365467646 AxlrVlvNmr11RtrtPrtMsrdFlw "Auxiliary valve number 11 retract port measured flow: Measured flow through the retract port of auxiliary valve number 11 of a tractor, expressed as a percentage of full flow. Zero percent indicates no flow, 100 % indicates maximum flow, −100 % indic...";
CM_ SG_ 2365467646 AxlrVlvNmr11RtrnPrtPrssr "Auxiliary valve number 11 return port pressure: Measured nominal pressure at the return port of auxiliary valve 11 of a tractor.";
CM_ SG_ 2365467646 AxlrVlvNmr11ExtndPrtPrssr "Auxiliary valve number 11 extend port pressure: Measured nominal pressure at the extend port of auxiliary valve 11 of a tractor.";
CM_ SG_ 2365467646 AxlrVlvNmr11RtrtPrtPrssr "Auxiliary valve number 11 retract port pressure: Measured nominal pressure at the retract port of auxiliary valve 11 of a tractor.";
CM_ SG_ 2365467646 AxlrVlvNmr11MsrdFlwLmtStts "Auxiliary valve number 11 measured flow limit status: This parameter is used to report the Tractor ECU's present measured flow limit status associated with valve number 11 flow commands that are persistent. Value Meaning 000 Not limited 001 Operator ...";
CM_ BO_ 2365467902 "Auxiliary valve 12 measured flow";
CM_ SG_ 2365467902 AxlrVlvNmr12ExtndPrtMsrdFlw "Auxiliary valve number 12 extend port measured flow: Measured flow through the extend port of auxiliary valve number 12 of a tractor, expressed as a percentage of full flow. Zero percent indicates no flow, 100 % indicates maximum flow, −100 % indicat...";
CM_ SG_ 2365467902 AxlrVlvNmr12RtrtPrtMsrdFlw "Auxiliary valve number 12 retract port measured flow: Measured flow through the retract port of auxiliary valve number 12 of a tractor, expressed as a percentage of full flow. Zero percent indicates no flow, 100 % indicates maximum flow, −100 % indic...";
CM_ SG_ 2365467902 AxlrVlvNmr12RtrnPrtPrssr "Auxiliary valve number 12 return port pressure: Measured nominal pressure at the return port of auxiliary valve 15 of a tractor.";
CM_ SG_ 2365467902 AxlrVlvNmr12ExtndPrtPrssr "Auxiliary valve number 12 extend port pressure: Measured nominal pressure at the extend port of auxiliary valve 12 of a tractor.";
CM_ SG_ 2365467902 AxlrVlvNmr12RtrtPrtPrssr "Auxiliary valve number 12 retract port pressure: Measured nominal pressure at the retract port of auxiliary valve 12 of a tractor.";
CM_ SG_ 2365467902 AxlrVlvNmr12MsrdFlwLmtStts "Auxiliary valve number 12 measured flow limit status: This parameter is used to report the Tractor ECU's present measured flow limit status associated with valve number 15 flow commands that are persistent. Value Meaning 000 Not limited 001 Operator ...";
CM_ BO_ 2365468158 "Auxiliary valve 13 measured flow";
CM_ SG_ 2365468158 AxlrVlvNmr13ExtndPrtMsrdFlw "Auxiliary valve number 13 extend port measured flow: Measured flow through the extend port of auxiliary valve number 15 of a tractor, expressed as a percentage of full flow. Zero percent indicates no flow, 100 % indicates maximum flow, −100 % indicat...";
CM_ SG_ 2365468158 AxlrVlvNmr13RtrtPrtMsrdFlw "Auxiliary valve number 13 retract port measured flow: Measured flow through the retract port of auxiliary valve number 15 of a tractor, expressed as a percentage of full flow. Zero percent indicates no flow, 100 % indicates maximum flow, −100 % indic...";
CM_ SG_ 2365468158 AxlrVlvNmr13RtrnPrtPrssr "Auxiliary valve number 13 return port pressure: Measured nominal pressure at the return port of auxiliary valve 15 of a tractor.";
CM_ SG_ 2365468158 AxlrVlvNmr13ExtndPrtPrssr "Auxiliary valve number 13 extend port pressure: Measured nominal pressure at the extend port of auxiliary valve 13 of a tractor.";
CM_ SG_ 2365468158 AxlrVlvNmr13RtrtPrtPrssr "Auxiliary valve number 13 retract port pressure: Measured nominal pressure at the retract port of auxiliary valve 13 of a tractor.";
CM_ SG_ 2365468158 AxlrVlvNmr13MsrdFlwLmtStts "Auxiliary valve number 13 measured flow limit status: This parameter is used to report the Tractor ECU's present measured flow limit status associated with valve number 15 flow commands that are persistent. Value Meaning 000 Not limited 001 Operator ...";
CM_ BO_ 2365468414 "Auxiliary valve 14 measured flow";
CM_ SG_ 2365468414 AxlrVlvNmr14ExtndPrtMsrdFlw "Auxiliary valve number 14 extend port measured flow: Measured flow through the extend port of auxiliary valve number 15 of a tractor, expressed as a percentage of full flow. Zero percent indicates no flow, 100 % indicates maximum flow, −100 % indicat...";
CM_ SG_ 2365468414 AxlrVlvNmr14RtrtPrtMsrdFlw "Auxiliary valve number 14 retract port measured flow: Measured flow through the retract port of auxiliary valve number 15 of a tractor, expressed as a percentage of full flow. Zero percent indicates no flow, 100 % indicates maximum flow, −100 % indic...";
CM_ SG_ 2365468414 AxlrVlvNmr14RtrnPrtPrssr "Auxiliary valve number 14 return port pressure: Measured nominal pressure at the return port of auxiliary valve 15 of a tractor.";
CM_ SG_ 2365468414 AxlrVlvNmr14ExtndPrtPrssr "Auxiliary valve number 14 extend port pressure: Measured nominal pressure at the extend port of auxiliary valve 14 of a tractor.";
CM_ SG_ 2365468414 AxlrVlvNmr14RtrtPrtPrssr "Auxiliary valve number 14 retract port pressure: Measured nominal pressure at the retract port of auxiliary valve 14 of a tractor.";
CM_ SG_ 2365468414 AxlrVlvNmr14MsrdFlwLmtStts "Auxiliary valve number 14 measured flow limit status: This parameter is used to report the Tractor ECU's present measured flow limit status associated with valve number 15 flow commands that are persistent. Value Meaning 000 Not limited 001 Operator ...";
CM_ BO_ 2365468670 "Auxiliary valve 15 measured flow";
CM_ SG_ 2365468670 AxlrVlvNmr15ExtndPrtMsrdFlw "Auxiliary valve number 15 extend port measured flow: Measured flow through the extend port of auxiliary valve number 15 of a tractor, expressed as a percentage of full flow. Zero percent indicates no flow, 100 % indicates maximum flow, −100 % indicat...";
CM_ SG_ 2365468670 AxlrVlvNmr15RtrtPrtMsrdFlw "Auxiliary valve number 15 retract port measured flow: Measured flow through the retract port of auxiliary valve number 15 of a tractor, expressed as a percentage of full flow. Zero percent indicates no flow, 100 % indicates maximum flow, −100 % indic...";
CM_ SG_ 2365468670 AxlrVlvNmr15RtrnPrtPrssr "Auxiliary valve number 15 return port pressure: Measured nominal pressure at the return port of auxiliary valve 15 of a tractor.";
CM_ SG_ 2365468670 AxlrVlvNmr15ExtndPrtPrssr "Auxiliary valve number 15 extend port pressure: Measured nominal pressure at the extend port of auxiliary valve 15 of a tractor.";
CM_ SG_ 2365468670 AxlrVlvNmr15RtrtPrtPrssr "Auxiliary valve number 15 retract port pressure: Measured nominal pressure at the retract port of auxiliary valve 15 of a tractor.";
CM_ SG_ 2365468670 AxlrVlvNmr15MsrdFlwLmtStts "Auxiliary valve number 15 measured flow limit status: This parameter is used to report the Tractor ECU's present measured flow limit status associated with valve number 01 flow commands that are persistent. Value Meaning 000 Not limited 001 Operator ...";
CM_ BO_ 2365468926 "Auxiliary valve 0 command";
CM_ SG_ 2365468926 AxlrVlvNmr0PrtFlwCmmnd "Auxiliary valve number 0 port flow — Command: Command for setting the flow through the extend or retract port of auxiliary valve 0 of a tractor, expressed as a percentage of full flow. Zero percent indicates no flow, 100 % indicates maximum flow; the...";
CM_ SG_ 2365468926 AxlrVlvNmr0RsltnMdCmmnd "Auxiliary valve number 0 Resolution mode — Command: Command to identify whether the extended resolution valve command (defined in Auxiliary valve number X port flow — Extended Resolution Command) is valid Value Meaning 00 Standard resolution paramete...";
CM_ SG_ 2365468926 AxlrVlvNmr0SttCmmnd "Auxiliary valve number 0 state — Command: Command for setting the auxiliary valve number 0 state. With float enabled, hydraulic fluid may flow to or from the tractor as driven by the implement. Value Meaning 0000 Block 0001 Extend 0010 Retract 0011 F...";
CM_ SG_ 2365468926 AxlrVlvNmr0FlSfMdCmmnd "Auxiliary valve number 0 fail safe mode — Command: Command for setting the fail safe mode of auxiliary valve number 0. Value Meaning 00 Block 01 Float 10 Reserved 11 Don't care";
CM_ SG_ 2365468926 AxVvN0PtFwExtddRstCd "Auxiliary valve number 0 port flow — Extended Resolution Command: Extended resolution command for setting the flow through the extend or retract port of auxiliary valve 0 of a tractor, expressed as a percentage of full flow. 0 % indicates no flow, 10...";
CM_ BO_ 2365469182 "Auxiliary valve 1 command";
CM_ SG_ 2365469182 AxlrVlvNmr1PrtFlwCmmnd "Auxiliary valve number 1 port flow — Command: Command for setting the flow through the extend or retract port of auxiliary valve 1 of a tractor, expressed as a percentage of full flow. Zero percent indicates no flow, 100 % indicates maximum flow; the...";
CM_ SG_ 2365469182 AxlrVlvNmr1RsltnMdCmmnd "Auxiliary valve number 1 Resolution mode — Command: Command to identify whether the extended resolution valve command (defined in Auxiliary valve number X port flow — Extended Resolution Command) is valid Value Meaning 00 Standard resolution paramete...";
CM_ SG_ 2365469182 AxlrVlvNmr1SttCmmnd "Auxiliary valve number 1 state — Command: Command for setting the auxiliary valve number 1 state. With float enabled, hydraulic fluid may flow to or from the tractor as driven by the implement. Value Meaning 0000 Block 0001 Extend 0010 Retract 0011 F...";
CM_ SG_ 2365469182 AxlrVlvNmr1FlSfMdCmmnd "Auxiliary valve number 1 fail safe mode — Command: Command for setting the fail safe mode of auxiliary valve number 1. Value Meaning 00 Block 01 Float 10 Reserved 11 Don't care";
CM_ SG_ 2365469182 AxVvN1PtFwExtddRstCd "Auxiliary valve number 1 port flow — Extended Resolution Command: Extended resolution command for setting the flow through the extend or retract port of auxiliary valve 1 of a tractor, expressed as a percentage of full flow. 0 % indicates no flow, 10...";
CM_ BO_ 2365469438 "Auxiliary valve 2 command";
CM_ SG_ 2365469438 AxlrVlvNmr2PrtFlwCmmnd "Auxiliary valve number 2 port flow — Command: Command for setting the flow through the extend or retract port of auxiliary valve 2 of a tractor, expressed as a percentage of full flow. Zero percent indicates no flow, 100 % indicates maximum flow; the...";
CM_ SG_ 2365469438 AxlrVlvNmr2RsltnMdCmmnd "Auxiliary valve number 2 Resolution mode — Command: Command to identify whether the extended resolution valve command (defined in Auxiliary valve number X port flow — Extended Resolution Command) is valid Value Meaning 00 Standard resolution paramete...";
CM_ SG_ 2365469438 AxlrVlvNmr2SttCmmnd "Auxiliary valve number 2 state — Command: Command for setting the auxiliary valve number 2 state. With float enabled, hydraulic fluid may flow to or from the tractor as driven by the implement. Value Meaning 0000 Block 0001 Extend 0010 Retract 0011 F...";
CM_ SG_ 2365469438 AxlrVlvNmr2FlSfMdCmmnd "Auxiliary valve number 2 fail safe mode — Command: Command for setting the fail safe mode of auxiliary valve number 2. Value Meaning 00 Block 01 Float 10 Reserved 11 Don't care";
CM_ SG_ 2365469438 AxVvN2PtFwExtddRstCd "Auxiliary valve number 2 port flow — Extended Resolution Command: Extended resolution command for setting the flow through the extend or retract port of auxiliary valve 2 of a tractor, expressed as a percentage of full flow. 0 % indicates no flow, 10...";
CM_ BO_ 2365469694 "Auxiliary valve 3 command";
CM_ SG_ 2365469694 AxlrVlvNmr3PrtFlwCmmnd "Auxiliary valve number 3 port flow — Command: Command for setting the flow through the extend or retract port of auxiliary valve 3 of a tractor, expressed as a percentage of full flow. Zero percent indicates no flow, 100 % indicates maximum flow; the...";
CM_ SG_ 2365469694 AxlrVlvNmr3RsltnMdCmmnd "Auxiliary valve number 3 Resolution mode — Command: Command to identify whether the extended resolution valve command (defined in Auxiliary valve number X port flow — Extended Resolution Command) is valid Value Meaning 00 Standard resolution paramete...";
CM_ SG_ 2365469694 AxlrVlvNmr3SttCmmnd "Auxiliary valve number 3 state — Command: Command for setting the auxiliary valve number 3 state. With float enabled, hydraulic fluid may flow to or from the tractor as driven by the implement. Value Meaning 0000 Block 0001 Extend 0010 Retract 0011 F...";
CM_ SG_ 2365469694 AxlrVlvNmr3FlSfMdCmmnd "Auxiliary valve number 3 fail safe mode — Command: Command for setting the fail safe mode of auxiliary valve number 3. Value Meaning 00 Block 01 Float 10 Reserved 11 Don't care";
CM_ SG_ 2365469694 AxVvN3PtFwExtddRstCd "Auxiliary valve number 3 port flow — Extended Resolution Command: Extended resolution command for setting the flow through the extend or retract port of auxiliary valve 3 of a tractor, expressed as a percentage of full flow. 0 % indicates no flow, 10...";
CM_ BO_ 2365469950 "Auxiliary valve 4 command";
CM_ SG_ 2365469950 AxlrVlvNmr4PrtFlwCmmnd "Auxiliary valve number 4 port flow — Command: Command for setting the flow through the extend or retract port of auxiliary valve 4 of a tractor, expressed as a percentage of full flow. Zero percent indicates no flow, 100 % indicates maximum flow; the...";
CM_ SG_ 2365469950 AxlrVlvNmr4RsltnMdCmmnd "Auxiliary valve number 4 Resolution mode — Command: Command to identify whether the extended resolution valve command (defined in Auxiliary valve number X port flow — Extended Resolution Command) is valid Value Meaning 00 Standard resolution paramete...";
CM_ SG_ 2365469950 AxlrVlvNmr4SttCmmnd "Auxiliary valve number 4 state — Command: Command for setting the auxiliary valve number 4 state. With float enabled, hydraulic fluid may flow to or from the tractor as driven by the implement. Value Meaning 0000 Block 0001 Extend 0010 Retract 0011 F...";
CM_ SG_ 2365469950 AxlrVlvNmr4FlSfMdCmmnd "Auxiliary valve number 4 fail safe mode — Command: Command for setting the fail safe mode of auxiliary valve number 4. Value Meaning 00 Block 01 Float 10 Reserved 11 Don't care";
CM_ SG_ 2365469950 AxVvN4PtFwExtddRstCd "Auxiliary valve number 4 port flow — Extended Resolution Command: Extended resolution command for setting the flow through the extend or retract port of auxiliary valve 4 of a tractor, expressed as a percentage of full flow. 0 % indicates no flow, 10...";
CM_ BO_ 2365470206 "Auxiliary valve 5 command";
CM_ SG_ 2365470206 AxlrVlvNmr5PrtFlwCmmnd "Auxiliary valve number 5 port flow — Command: Command for setting the flow through the extend or retract port of auxiliary valve 5 of a tractor, expressed as a percentage of full flow. Zero percent indicates no flow, 100 % indicates maximum flow; the...";
CM_ SG_ 2365470206 AxlrVlvNmr5RsltnMdCmmnd "Auxiliary valve number 5 Resolution mode — Command: Command to identify whether the extended resolution valve command (defined in Auxiliary valve number X port flow — Extended Resolution Command) is valid Value Meaning 00 Standard resolution paramete...";
CM_ SG_ 2365470206 AxlrVlvNmr5SttCmmnd "Auxiliary valve number 5 state — Command: Command for setting the auxiliary valve number 5 state. With float enabled, hydraulic fluid may flow to or from the tractor as driven by the implement. Value Meaning 0000 Block 0001 Extend 0010 Retract 0011 F...";
CM_ SG_ 2365470206 AxlrVlvNmr5FlSfMdCmmnd "Auxiliary valve number 5 fail safe mode — Command: Command for setting the fail safe mode of auxiliary valve number 5. Value Meaning 00 Block 01 Float 10 Reserved 11 Don't care";
CM_ SG_ 2365470206 AxVvN5PtFwExtddRstCd "Auxiliary valve number 5 port flow — Extended Resolution Command: Extended resolution command for setting the flow through the extend or retract port of auxiliary valve 5 of a tractor, expressed as a percentage of full flow. 0 % indicates no flow, 10...";
CM_ BO_ 2365470462 "Auxiliary valve 6 command";
CM_ SG_ 2365470462 AxlrVlvNmr6PrtFlwCmmnd "Auxiliary valve number 6 port flow — Command: Command for setting the flow through the extend or retract port of auxiliary valve 6 of a tractor, expressed as a percentage of full flow. Zero percent indicates no flow, 100 % indicates maximum flow; the...";
CM_ SG_ 2365470462 AxlrVlvNmr6RsltnMdCmmnd "Auxiliary valve number 6 Resolution mode — Command: Command to identify whether the extended resolution valve command (defined in Auxiliary valve number X port flow — Extended Resolution Command) is valid Value Meaning 00 Standard resolution paramete...";
CM_ SG_ 2365470462 AxlrVlvNmr6SttCmmnd "Auxiliary valve number 6 state — Command: Command for setting the auxiliary valve number 6 state. With float enabled, hydraulic fluid may flow to or from the tractor as driven by the implement. Value Meaning 0000 Block 0001 Extend 0010 Retract 0011 F...";
CM_ SG_ 2365470462 AxlrVlvNmr6FlSfMdCmmnd "Auxiliary valve number 6 fail safe mode — Command: Command for setting the fail safe mode of auxiliary valve number 6. Value Meaning 00 Block 01 Float 10 Reserved 11 Don't care";
CM_ SG_ 2365470462 AxVvN6PtFwExtddRstCd "Auxiliary valve number 6 port flow — Extended Resolution Command: Extended resolution command for setting the flow through the extend or retract port of auxiliary valve 6 of a tractor, expressed as a percentage of full flow. 0 % indicates no flow, 10...";
CM_ BO_ 2365470718 "Auxiliary valve 7 command";
CM_ SG_ 2365470718 AxlrVlvNmr7PrtFlwCmmnd "Auxiliary valve number 7 port flow — Command: Command for setting the flow through the extend or retract port of auxiliary valve 7 of a tractor, expressed as a percentage of full flow. Zero percent indicates no flow, 100 % indicates maximum flow; the...";
CM_ SG_ 2365470718 AxlrVlvNmr7RsltnMdCmmnd "Auxiliary valve number 7 Resolution mode — Command: Command to identify whether the extended resolution valve command (defined in Auxiliary valve number X port flow — Extended Resolution Command) is valid Value Meaning 00 Standard resolution paramete...";
CM_ SG_ 2365470718 AxlrVlvNmr7SttCmmnd "Auxiliary valve number 7 state — Command: Command for setting the auxiliary valve number 7 state. With float enabled, hydraulic fluid may flow to or from the tractor as driven by the implement. Value Meaning 0000 Block 0001 Extend 0010 Retract 0011 F...";
CM_ SG_ 2365470718 AxlrVlvNmr7FlSfMdCmmnd "Auxiliary valve number 7 fail safe mode — Command: Command for setting the fail safe mode of auxiliary valve number 7. Value Meaning 00 Block 01 Float 10 Reserved 11 Don't care";
CM_ SG_ 2365470718 AxVvN7PtFwExtddRstCd "Auxiliary valve number 7 port flow — Extended Resolution Command: Extended resolution command for setting the flow through the extend or retract port of auxiliary valve 7 of a tractor, expressed as a percentage of full flow. 0 % indicates no flow, 10...";
CM_ BO_ 2365470974 "Auxiliary valve 8 command";
CM_ SG_ 2365470974 AxlrVlvNmr8PrtFlwCmmnd "Auxiliary valve number 8 port flow — Command: Command for setting the flow through the extend or retract port of auxiliary valve 8 of a tractor, expressed as a percentage of full flow. Zero percent indicates no flow, 100 % indicates maximum flow; the...";
CM_ SG_ 2365470974 AxlrVlvNmr8RsltnMdCmmnd "Auxiliary valve number 8 Resolution mode — Command: Command to identify whether the extended resolution valve command (defined in Auxiliary valve number X port flow — Extended Resolution Command) is valid Value Meaning 00 Standard resolution paramete...";
CM_ SG_ 2365470974 AxlrVlvNmr8SttCmmnd "Auxiliary valve number 8 state — Command: Command for setting the auxiliary valve number 8 state. With float enabled, hydraulic fluid may flow to or from the tractor as driven by the implement. Value Meaning 0000 Block 0001 Extend 0010 Retract 0011 F...";
CM_ SG_ 2365470974 AxlrVlvNmr8FlSfMdCmmnd "Auxiliary valve number 8 fail safe mode — Command: Command for setting the fail safe mode of auxiliary valve number 8. Value Meaning 00 Block 01 Float 10 Reserved 11 Don't care";
CM_ SG_ 2365470974 AxVvN8PtFwExtddRstCd "Auxiliary valve number 8 port flow — Extended Resolution Command: Extended resolution command for setting the flow through the extend or retract port of auxiliary valve 8 of a tractor, expressed as a percentage of full flow. 0 % indicates no flow, 10...";
CM_ BO_ 2365471230 "Auxiliary valve 9 command";
CM_ SG_ 2365471230 AxlrVlvNmr9PrtFlwCmmnd "Auxiliary valve number 9 port flow — Command: Command for setting the flow through the extend or retract port of auxiliary valve 9 of a tractor, expressed as a percentage of full flow. Zero percent indicates no flow, 100 % indicates maximum flow; the...";
CM_ SG_ 2365471230 AxlrVlvNmr9RsltnMdCmmnd "Auxiliary valve number 9 Resolution mode — Command: Command to identify whether the extended resolution valve command (defined in Auxiliary valve number X port flow — Extended Resolution Command) is valid Value Meaning 00 Standard resolution paramete...";
CM_ SG_ 2365471230 AxlrVlvNmr9SttCmmnd "Auxiliary valve number 9 state — Command: Command for setting the auxiliary valve number 9 state. With float enabled, hydraulic fluid may flow to or from the tractor as driven by the implement. Value Meaning 0000 Block 0001 Extend 0010 Retract 0011 F...";
CM_ SG_ 2365471230 AxlrVlvNmr9FlSfMdCmmnd "Auxiliary valve number 9 fail safe mode — Command: Command for setting the fail safe mode of auxiliary valve number 9. Value Meaning 00 Block 01 Float 10 Reserved 11 Don't care";
CM_ SG_ 2365471230 AxVvN9PtFwExtddRstCd "Auxiliary valve number 9 port flow — Extended Resolution Command: Extended resolution command for setting the flow through the extend or retract port of auxiliary valve 9 of a tractor, expressed as a percentage of full flow. 0 % indicates no flow, 10...";
CM_ BO_ 2365471486 "Auxiliary valve 10 command";
CM_ SG_ 2365471486 AxlrVlvNmr10PrtFlwCmmnd "Auxiliary valve number 10 port flow — Command: Command for setting the flow through the extend or retract port of auxiliary valve 10 of a tractor, expressed as a percentage of full flow. Zero percent indicates no flow, 100 % indicates maximum flow; t...";
CM_ SG_ 2365471486 AxlrVlvNmr10RsltnMdCmmnd "Auxiliary valve number 10 Resolution mode — Command: Command to identify whether the extended resolution valve command (defined in Auxiliary valve number X port flow — Extended Resolution Command) is valid Value Meaning 00 Standard resolution paramet...";
CM_ SG_ 2365471486 AxlrVlvNmr10SttCmmnd "Auxiliary valve number 10 state — Command: Command for setting the auxiliary valve number 10 state. With float enabled, hydraulic fluid may flow to or from the tractor as driven by the implement. Value Meaning 0000 Block 0001 Extend 0010 Retract 0011...";
CM_ SG_ 2365471486 AxlrVlvNmr10FlSfMdCmmnd "Auxiliary valve number 10 fail safe mode — Command: Command for setting the fail safe mode of auxiliary valve number 10. Value Meaning 00 Block 01 Float 10 Reserved 11 Don't care";
CM_ SG_ 2365471486 AxVvN10PtFwExtddRstCd "Auxiliary valve number 10 port flow — Extended Resolution Command: Extended resolution command for setting the flow through the extend or retract port of auxiliary valve 10 of a tractor, expressed as a percentage of full flow. 0 % indicates no flow, ...";
CM_ BO_ 2365471742 "Auxiliary valve 11 command";
CM_ SG_ 2365471742 AxlrVlvNmr11PrtFlwCmmnd "Auxiliary valve number 11 port flow — Command: Command for setting the flow through the extend or retract port of auxiliary valve 11 of a tractor, expressed as a percentage of full flow. Zero percent indicates no flow, 100 % indicates maximum flow; t...";
CM_ SG_ 2365471742 AxlrVlvNmr11RsltnMdCmmnd "Auxiliary valve number 11 Resolution mode — Command: Command to identify whether the extended resolution valve command (defined in Auxiliary valve number X port flow — Extended Resolution Command) is valid Value Meaning 00 Standard resolution paramet...";
CM_ SG_ 2365471742 AxlrVlvNmr11SttCmmnd "Auxiliary valve number 11 state — Command: Command for setting the auxiliary valve number 11 state. With float enabled, hydraulic fluid may flow to or from the tractor as driven by the implement. Value Meaning 0000 Block 0001 Extend 0010 Retract 0011...";
CM_ SG_ 2365471742 AxlrVlvNmr11FlSfMdCmmnd "Auxiliary valve number 11 fail safe mode — Command: Command for setting the fail safe mode of auxiliary valve number 11. Value Meaning 00 Block 01 Float 10 Reserved 11 Don't care";
CM_ SG_ 2365471742 AxVvN11PtFwExtddRstCd "Auxiliary valve number 11 port flow — Extended Resolution Command: Extended resolution command for setting the flow through the extend or retract port of auxiliary valve 11 of a tractor, expressed as a percentage of full flow. 0 % indicates no flow, ...";
CM_ BO_ 2365471998 "Auxiliary valve 12 command";
CM_ SG_ 2365471998 AxlrVlvNmr12PrtFlwCmmnd "Auxiliary valve number 12 port flow — Command: Command for setting the flow through the extend or retract port of auxiliary valve 12 of a tractor, expressed as a percentage of full flow. Zero percent indicates no flow, 100 % indicates maximum flow; t...";
CM_ SG_ 2365471998 AxlrVlvNmr12RsltnMdCmmnd "Auxiliary valve number 12 Resolution mode — Command: Command to identify whether the extended resolution valve command (defined in Auxiliary valve number X port flow — Extended Resolution Command) is valid Value Meaning 00 Standard resolution paramet...";
CM_ SG_ 2365471998 AxlrVlvNmr12SttCmmnd "Auxiliary valve number 12 state — Command: Command for setting the auxiliary valve number 12 state. With float enabled, hydraulic fluid may flow to or from the tractor as driven by the implement. Value Meaning 0000 Block 0001 Extend 0010 Retract 0011...";
CM_ SG_ 2365471998 AxlrVlvNmr12FlSfMdCmmnd "Auxiliary valve number 12 fail safe mode — Command: Command for setting the fail safe mode of auxiliary valve number 12. Value Meaning 00 Block 01 Float 10 Reserved 11 Don't care";
CM_ SG_ 2365471998 AxVvN12PtFwExtddRstCd "Auxiliary valve number 12 port flow — Extended Resolution Command: Extended resolution command for setting the flow through the extend or retract port of auxiliary valve 12 of a tractor, expressed as a percentage of full flow. 0 % indicates no flow, ...";
CM_ BO_ 2365472254 "Auxiliary valve 13 command";
CM_ SG_ 2365472254 AxlrVlvNmr13PrtFlwCmmnd "Auxiliary valve number 13 port flow — Command: Command for setting the flow through the extend or retract port of auxiliary valve 13 of a tractor, expressed as a percentage of full flow. Zero percent indicates no flow, 100 % indicates maximum flow; t...";
CM_ SG_ 2365472254 AxlrVlvNmr13RsltnMdCmmnd "Auxiliary valve number 13 Resolution mode — Command: Command to identify whether the extended resolution valve command (defined in Auxiliary valve number X port flow — Extended Resolution Command) is valid Value Meaning 00 Standard resolution paramet...";
CM_ SG_ 2365472254 AxlrVlvNmr13SttCmmnd "Auxiliary valve number 13 state — Command: Command for setting the auxiliary valve number 13 state. With float enabled, hydraulic fluid may flow to or from the tractor as driven by the implement. Value Meaning 0000 Block 0001 Extend 0010 Retract 0011...";
CM_ SG_ 2365472254 AxlrVlvNmr13FlSfMdCmmnd "Auxiliary valve number 13 fail safe mode — Command: Command for setting the fail safe mode of auxiliary valve number 13. Value Meaning 00 Block 01 Float 10 Reserved 11 Don't care";
CM_ SG_ 2365472254 AxVvN13PtFwExtddRstCd "Auxiliary valve number 13 port flow — Extended Resolution Command: Extended resolution command for setting the flow through the extend or retract port of auxiliary valve 13 of a tractor, expressed as a percentage of full flow. 0 % indicates no flow, ...";
CM_ BO_ 2365472510 "Auxiliary valve 14 command";
CM_ SG_ 2365472510 AxlrVlvNmr14PrtFlwCmmnd "Auxiliary valve number 14 port flow — Command: Command for setting the flow through the extend or retract port of auxiliary valve 14 of a tractor, expressed as a percentage of full flow. Zero percent indicates no flow, 100 % indicates maximum flow; t...";
CM_ SG_ 2365472510 AxlrVlvNmr14RsltnMdCmmnd "Auxiliary valve number 14 Resolution mode — Command: Command to identify whether the extended resolution valve command (defined in Auxiliary valve number X port flow — Extended Resolution Command) is valid Value Meaning 00 Standard resolution paramet...";
CM_ SG_ 2365472510 AxlrVlvNmr14SttCmmnd "Auxiliary valve number 14 state — Command: Command for setting the auxiliary valve number 14 state. With float enabled, hydraulic fluid may flow to or from the tractor as driven by the implement. Value Meaning 0000 Block 0001 Extend 0010 Retract 0011...";
CM_ SG_ 2365472510 AxlrVlvNmr14FlSfMdCmmnd "Auxiliary valve number 14 fail safe mode — Command: Command for setting the fail safe mode of auxiliary valve number 14. Value Meaning 00 Block 01 Float 10 Reserved 11 Don't care";
CM_ SG_ 2365472510 AxVvN14PtFwExtddRstCd "Auxiliary valve number 14 port flow — Extended Resolution Command: Extended resolution command for setting the flow through the extend or retract port of auxiliary valve 14 of a tractor, expressed as a percentage of full flow. 0 % indicates no flow, ...";
CM_ BO_ 2365472766 "Auxiliary valve 15 command";
CM_ SG_ 2365472766 AxlrVlvNmr15PrtFlwCmmnd "Auxiliary valve number 15 port flow — Command: Command for setting the flow through the extend or retract port of auxiliary valve 15 of a tractor, expressed as a percentage of full flow. Zero percent indicates no flow, 100 % indicates maximum flow; t...";
CM_ SG_ 2365472766 AxlrVlvNmr15RsltnMdCmmnd "Auxiliary valve number 15 Resolution mode — Command: Command to identify whether the extended resolution valve command (defined in Auxiliary valve number X port flow — Extended Resolution Command) is valid Value Meaning 00 Standard resolution paramet...";
CM_ SG_ 2365472766 AxlrVlvNmr15SttCmmnd "Auxiliary valve number 15 state — Command: Command for setting the auxiliary valve number 15 state. With float enabled, hydraulic fluid may flow to or from the tractor as driven by the implement. Value Meaning 0000 Block 0001 Extend 0010 Retract 0011...";
CM_ SG_ 2365472766 AxlrVlvNmr15FlSfMdCmmnd "Auxiliary valve number 15 fail safe mode — Command: Command for setting the fail safe mode of auxiliary valve number 15. Value Meaning 00 Block 01 Float 10 Reserved 11 Don't care";
CM_ SG_ 2365472766 AxVvN15PtFwExtddRstCd "Auxiliary valve number 15 port flow — Extended Resolution Command: Extended resolution command for setting the flow through the extend or retract port of auxiliary valve 15 of a tractor, expressed as a percentage of full flow. 0 % indicates no flow, ...";
CM_ BO_ 2365473534 "Hitch and PTO commands";
CM_ SG_ 2365473534 FrontHitchPositionCommand "Front hitch position — Command: Command for allowing the position of the front three-point hitch to be set; it is expressed as a percentage of full travel: 0 % indicates the full down position; 100 %, the full up position.";
CM_ SG_ 2365473534 RearHitchPositionCommand "Rear hitch position — Command: Command for allowing the position of the rear three-point hitch to be set; it is expressed as a percentage of full travel: 0 % indicates the full down position; 100 %, the full up position.";
CM_ SG_ 2365473534 FrntPtOtptShftSpdStPntCmmnd "Front PTO output shaft speed set point — Command: Command for setting the rotational speed of the front power take-off (PTO) output shaft.";
CM_ SG_ 2365473534 RrPtOtptShftSpdStPntCmmnd "Rear PTO output shaft speed set point — Command: Command for setting the rotational speed of the rear power take-off (PTO) output shaft.";
CM_ SG_ 2365473534 RearPtoEngagementCommand "Rear PTO engagement — Command: Command for engaging or disengaging the rear power take-off (PTO). Value  Meaning 00       Disengage PTO 01       Engage PTO 10       Reserved 11       Don't care";
CM_ SG_ 2365473534 FrontPtoEngagementCommand "Front PTO engagement — Command: Command for engaging or disengaging the front power take-off (PTO). Value Meaning 00      Disengage PTO 01      Engage PTO 10      Reserved 11      Don't care";
CM_ SG_ 2365473534 RearPtoEconomyModeCommand "Rear PTO economy mode — Command: Command for engaging and disengaging the rear power take-off (PTO) economy mode. Value Meaning 00      Disengage PTO economy mode 01      Engage PTO economy mode 10      Reserved 11      Don't care";
CM_ SG_ 2365473534 FrontPtoEconomyModeCommand "Front PTO economy mode — Command: Command for engaging and disengaging the front power take-off (PTO) economy mode. Value Meaning 00      Disengage PTO economy mode 01      Engage PTO economy mode 10      Reserved 11      Don't care";
CM_ SG_ 2365473534 RearPtoModeCommand "Rear PTO mode — Command: Command for selecting the mode of the rear power take-off (PTO). Value Meaning 00      Select 540 r/min mode 01      Select 1 000 r/min mode 10      Reserved 11      Don't care";
CM_ SG_ 2365473534 FrontPtoModeCommand "Front PTO mode — Command: Command for selecting the mode of the front power take-off (PTO). Value Meaning 00      Select 540 r/min mode 01      Select 1 000 r/min mode 10      Reserved 11      Don't care";
CM_ BO_ 2365473790 "Primary or Rear Power Take off Output Shaft";
CM_ SG_ 2365473790 RearPtoOutputShaftSpeed "Rear PTO output shaft speed: Measured rotational speed of the rear power take-off (PTO) output shaft. For existing tractors that monitor PTO speed prior to the engagement clutch, the PTO speed will only be valid when PTO is engaged, and will be unava...";
CM_ SG_ 2365473790 RearPtoOutputShaftSpeedSetPoint "Rear PTO Output Shaft Speed Set Point: Measured value of the set point of the rotational speed of the rear power take-off (PTO) output shaft.";
CM_ SG_ 2365473790 RearPtoEngagementRequestStatus "Rear PTO engagement request status: This parameter is used to report the Tractor ECU's status associated with rear PTO engagement requests that are transient/temporary/one-shot. Value Meaning 00 External request accepted. No subsequent operator inter...";
CM_ SG_ 2365473790 RearPowerTakeOffEconomyMode "Rear Power Take Off Economy Mode: Measured signal indicating that the rear power take-off (PTO) economy mode is engaged or disengaged. Economy mode PTO operates at 540 r/min or 1 000 r/min at lower engine revolutions. Value Meaning 00 PTO economy mod...";
CM_ SG_ 2365473790 RearPowerTakeOffMode "Rear Power Take Off Mode: Measured signal indicating that the rear power take-off (PTO) mode is either 540 r/min or 1 000 r/min. Value Meaning 00 PTO mode is 540 r/min 01 PTO mode is 1 000 r/min 10 Error indication 11 Not available";
CM_ SG_ 2365473790 RearPowerTakeOffEngagement "Rear Power Take Off Engagement: Measured signal indicating that the rear power take-off (PTO) is engaged or disengaged. Value Meaning 00 PTO disengaged 01 PTO engaged 10 Error indication 11 Not available";
CM_ SG_ 2365473790 RearPtoShaftSpeedLimitStatus "Rear PTO shaft speed limit status: This parameter is used to report the Tractor ECU's present limit status associated with rear PTO shaft speed commands that are persistent. Value Meaning 000 Not limited 001 Operator limited/controlled (request canno...";
CM_ SG_ 2365473790 RearPtoEconomyModeRequestStatus "Rear PTO Economy mode request status: This parameter is used to report the Tractor ECU's status associated with rear PTO economy mode requests that are transient/temporary/one-shot. Value Meaning 00 External request accepted. No subsequent operator i...";
CM_ SG_ 2365473790 RearPtoModeRequestStatus "Rear PTO mode request status: This parameter is used to report the Tractor ECU's status associated with rear PTO mode requests that are transient/temporary/one-shot. Value Meaning00 External request accepted. No subsequent operator intervention. 01 C...";
CM_ SG_ 2365473790 RearPtoExitReasonCode "Rear PTO exit/reason code: This parameter is used to indicate why the rear PTO cannot accept remote commands or has most recently stopped accepting remote commands.Value Meaning 000000 No reason/all clear 000001 Required level of operator presence/aw...";
CM_ BO_ 2365474046 "Secondary or Front Power Take off Output Shaft";
CM_ SG_ 2365474046 FrontPtoOutputShaftSpeed "Front PTO output shaft speed: Measured rotational speed of the front power take-off (PTO) output shaft. For existing tractors that monitor PTO speed prior to the engagement clutch, the PTO speed will only be valid when PTO is engaged, and will be una...";
CM_ SG_ 2365474046 FrntPtOtptShftSpdStPnt "Front PTO Output Shaft Speed Set Point: Measured value of the set point of the rotational speed of the front power take-off (PTO) output shaft.";
CM_ SG_ 2365474046 FrontPtoEngagementRequestStatus "Front PTO engagement request status: This parameter is used to report the Tractor ECU's status associated with front PTO engagement requests that are transient/temporary/one-shot. Value Meaning 00 External request accepted. No subsequent operator int...";
CM_ SG_ 2365474046 FrontPowerTakeOffEconomyMode "Front Power Take Off Economy Mode: Measured signal indicating that the front power take-off (PTO) economy mode is engaged or disengaged. Economy mode PTO operates at 540 r/min or 1 000 r/min at lower engine revolutions. Value Meaning 00 PTO economy m...";
CM_ SG_ 2365474046 FrontPowerTakeOffMode "Front Power Take Off Mode: Measured signal indicating that the front power take-off (PTO) mode is either 540 r/min or 1 000 r/min. Value Meaning 00 PTO mode is 540 r/min 01 PTO mode is 1 000 r/min 10 Error indication 11 Not available";
CM_ SG_ 2365474046 FrontPowerTakeOffEngagement "Front Power Take Off Engagement: Measured signal indicating that the front power take-off (PTO) is engaged or disengaged.Value Meaning 00 PTO disengaged 01 PTO engaged 10 Error indication 11 Not available";
CM_ SG_ 2365474046 FrontPtoShaftSpeedLimitStatus "Front PTO shaft speed limit status: This parameter is used to report the Tractor ECU's present limit status associated with front PTO shaft speed commands that are persistent. Value Meaning 000 Not limited 001 Operator limited/controlled (request can...";
CM_ SG_ 2365474046 FrntPtEnmMdRqstStts "Front PTO Economy mode request status: This parameter is used to report the Tractor ECU's status associated with front PTO economy mode requests that are transient/temporary/one-shot. Value Meaning 00 External request accepted. No subsequent operator...";
CM_ SG_ 2365474046 FrontPtoModeRequestStatus "Front PTO mode request status: This parameter is used to report the Tractor ECU's status associated with front PTO mode requests that are transient/temporary/one-shot. Value Meaning 00 External request accepted. No subsequent operator intervention. 0...";
CM_ SG_ 2365474046 FrontPtoExitReasonCode "Front PTO exit/reason code: This parameter is used to indicate why the front PTO cannot accept remote commands or has most recently stopped accepting remote commands.Value Meaning 000000 No reason/all clear 000001 Required level of operator presence/...";
CM_ BO_ 2365474302 "Primary or Rear Hitch Status";
CM_ SG_ 2365474302 RearHitchPosition "Rear Hitch Position: Measured position of the rear three-point hitch; it is expressed as a percentage of full travel: 0 % indicates the full down position; 100 %, the full up position.";
CM_ SG_ 2365474302 RearHitchPositionLimitStatus "Rear Hitch Position Limit status: This parameter is used to report the Tractor ECU's present limit status associated with the rear hitch position commands that are persistent.Value Meaning 000 Not limited 001 Operator limited/controlled (request cann...";
CM_ SG_ 2365474302 RearHitchInWorkIndication "Rear Hitch In-work Indication: Measured signal indicating that the rear hitch is positioned below (in-work) or above (out-of-work) an adjustable switching threshold. The method of determining the switching threshold is not standardized and is to be d...";
CM_ SG_ 2365474302 RearNominalLowerLinkForce "Rear Nominal Lower Link Force: Measurement providing an indication of draft at the lower links of the rear three-point hitch. Nominal lower link force may be expected to be approximately linear with respect to draft and may be proportional to draft f...";
CM_ SG_ 2365474302 RearDraft "Rear Draft: Apparent horizontal force applied to the rear hitch by an implement. A positive value indicates the force applied to the tractor opposed to its forward direction of travel.";
CM_ SG_ 2365474302 RearHitchExitReasonCode "Rear hitch exit/reason code: This parameter is used to indicate why the rear hitch cannot accept remote commands or has most recently stopped accepting remote commands. Value Meaning 000000 No reason/all clear 000001 Required level of operator presen...";
CM_ BO_ 2365474558 "Secondary or Front Hitch Status";
CM_ SG_ 2365474558 FrontHitchPosition "Front Hitch Position: Measured position of the front three-point hitch; it is expressed as a percentage of full travel: 0 % indicates the full down position; 100 %, the full up position.";
CM_ SG_ 2365474558 FrontHitchPositionLimitStatus "Front Hitch Position Limit status: This parameter is used to report the Tractor ECU's present limit status associated with front hitch position commands that are persistent. Value Meaning 000 Not limited 001 Operator limited/controlled (request canno...";
CM_ SG_ 2365474558 FrontHitchInWorkIndication "Front Hitch In-work Indication: Measured signal indicating that the front hitch is positioned below (in-work) or above (out-of-work) an adjustable switching threshold. The method of determining the switching threshold is not standardized and is to be...";
CM_ SG_ 2365474558 FrontNominalLowerLinkForce "Front Nominal Lower Link Force: Measurement providing an indication of draft at the lower links of the front three-point hitch. Nominal lower link force may be expected to be approximately linear with respect to draft and may be proportional to draft...";
CM_ SG_ 2365474558 FrontDraft "Front Draft: Apparent horizontal force applied to the front hitch by an implement. A positive value indicates the force applied to the tractor opposed to its forward direction of travel.";
CM_ SG_ 2365474558 FrontHitchExitReasonCode "Front hitch exit/reason code: This parameter is used to indicate why the front hitch cannot accept remote commands or has most recently stopped accepting remote commands. Value Meaning 000000 No reason/all clear 000001 Required level of operator pres...";
CM_ BO_ 2566801406 "Maintain Power";
CM_ SG_ 2566801406 MaintainAcuatorPower "Maintain Acuator Power: Request to the Tractor ECU to maintain PWR power for the next 2 s. Value Meaning 00 No further requirement for PWR 01 Requirement for 2 s more for PWR 10 Reserved 11 Don't care";
CM_ SG_ 2566801406 MaintainEcuPower "Maintain ECU Power: Request to the Tractor ECU to maintain ECU_PWR power for the next 2 s.Value Meaning 00 No further requirement for ECU_PWR 01 Requirement for 2 s more of ECU_PWR 10 Reserved 11 Don't care";
CM_ SG_ 2566801406 ImplementInWorkState "Implement in-work state: Indicates that an implement is connected to a tractor or power unit and is in work state. Value Meaning 00 Implement is not in work state 01 Implement is in work state 10 Error indication 11 Not available";
CM_ SG_ 2566801406 ImplementReadyToWorkState "Implement ready-to-work state: Indicates that an implement is connected to a tractor or power unit and is ready for work. Value Meaning 00 Implement is not ready for field work 01 Implement is ready for field work 10 Error indication 11 Not available...";
CM_ SG_ 2566801406 ImplementParkState "Implement Park state: Indicates the state of an implement where it may be disconnected from a tractor or power unit. Value Meaning 00 Implement may not be disconnected 01 Implement may be disconnected 10 Error indication 11 Not available";
CM_ SG_ 2566801406 ImplementTransportState "Implement Transport state: Indicates the transport state of an implement connected to a tractor or power unit. Value Meaning 00 Implement may not be transported 01 Implement may be transported 10 Error indication 11 Not available";
CM_ BO_ 2365475070 "Wheel-based Speed and Distance";
CM_ SG_ 2365475070 WheelBasedMachineSpeed "Wheel-based machine speed: The value of the speed of a machine as calculated from the measured wheel or tail-shaft speed.";
CM_ SG_ 2365475070 WheelBasedMachineDistance "Wheel-based machine distance: Distance travelled by a machine as calculated from wheel or tail-shaft speed. When the distance exceeds 4 211 081,215 m, the value shall be reset to zero and incremented as additional distance accrues.";
CM_ SG_ 2365475070 MaximumTimeOfTractorPower "Maximum Time of Tractor Power: Maximum time of remaining tractor or power-unit-supplied electrical power at the current load. This parameter may be estimated rather than being a measured value.";
CM_ SG_ 2365475070 WheelBasedMachineDirection "Wheel-based machine direction: Measured signal indicating either forward or reverse as the direction of travel. When the speed is zero, indicate the last travel direction until a different direction is detected or selected and engaged. Value Meaning0...";
CM_ SG_ 2365475070 KeySwitchState "Key switch state: Indicates the key switch state of the tractor or power unit. This does not indicate unforeseen power interruptions such as those caused by starting the engine.Value Meaning00 Key switch Off01 Key switch not Off10 Error indication11 ...";
CM_ SG_ 2365475070 ImplementStartStopOperations "Implement Start/Stop operations: State of a switch or other operator input to start or enable implement operations. The start or enabled state can be the result of the implement being positioned in an operating position. It can be generated by an ope...";
CM_ SG_ 2365475070 OperatorDirectionReversed "Operator direction reversed: This parameter indicates whether the reported direction is reversed from the perspective of the operator (e.g. the operator station has been reversed such that forward direction actually moves the operator backwards). Val...";
CM_ BO_ 2365475326 "Ground-based Speed and Distance";
CM_ SG_ 2365475326 GroundBasedMachineSpeed "Ground-based machine speed: Actual ground speed of a machine, measured by a sensor such as that is not susceptible to wheel slip (e.g. radar, GPS, LIDAR, or stationary object tracking).";
CM_ SG_ 2365475326 GroundBasedMachineDistance "Ground-based machine distance: Actual distance travelled by a machine, based on measurements from a sensor such as that is not susceptible to wheel slip (e.g. radar, GPS, LIDAR, or stationary object tracking).When the distance exceeds 4 211 081,215 m...";
CM_ SG_ 2365475326 GroundBasedMachineDirection "Ground-based machine direction: Measured signal indicating either forward or reverse as the direction of travel. When the speed is zero, indicate the last travel direction until a different direction is detected. Value Meaning00 Reverse01 Forward10 E...";
BA_DEF_ SG_  "SPN" INT 0 524287;
BA_DEF_ BO_  "VFrameFormat" ENUM  "StandardCAN","ExtendedCAN","reserved","J1939PG";
BA_DEF_DEF_  "SPN" 0;
BA_DEF_DEF_  "VFrameFormat" "J1939PG";
BA_ "SPN" SG_ 2365462014 AxlrVlvNmr05ExtndPrtEstmtdFlw 1961;
BA_ "SPN" SG_ 2365462014 AxlrVlvNmr05RtrtPrtEstmtdFlw 1962;
BA_ "SPN" SG_ 2365462014 AxlrVlvNmr05VlvStt 1963;
BA_ "SPN" SG_ 2365462014 AuxiliaryValve05FailSafeMode 1970;
BA_ "SPN" SG_ 2365462014 AxlrVlvNmr05EstmtdFlwLmtStts 5171;
BA_ "SPN" SG_ 2365462014 AuxiliaryValve05ExitReasonCode 5805;
BA_ "SPN" SG_ 2365462014 AxlrVlv05EstmtdFlwHghRsltn 9737;
BA_ "SPN" SG_ 2365462270 AxlrVlvNmr06ExtndPrtEstmtdFlw 1973;
BA_ "SPN" SG_ 2365462270 AxlrVlvNmr06RtrtPrtEstmtdFlw 1974;
BA_ "SPN" SG_ 2365462270 AxlrVlvNmr06VlvStt 1975;
BA_ "SPN" SG_ 2365462270 AuxiliaryValve06FailSafeMode 1982;
BA_ "SPN" SG_ 2365462270 AxlrVlvNmr06EstmtdFlwLmtStts 5173;
BA_ "SPN" SG_ 2365462270 AuxiliaryValve06ExitReasonCode 5806;
BA_ "SPN" SG_ 2365462270 AxlrVlv06EstmtdFlwHghRsltn 9738;
BA_ "SPN" SG_ 2365462526 AxlrVlvNmr07ExtndPrtEstmtdFlw 1985;
BA_ "SPN" SG_ 2365462526 AxlrVlvNmr07RtrtPrtEstmtdFlw 1986;
BA_ "SPN" SG_ 2365462526 AxlrVlvNmr07VlvStt 1987;
BA_ "SPN" SG_ 2365462526 AuxiliaryValve07FailSafeMode 1994;
BA_ "SPN" SG_ 2365462526 AxlrVlvNmr07EstmtdFlwLmtStts 5175;
BA_ "SPN" SG_ 2365462526 AuxiliaryValve07ExitReasonCode 5807;
BA_ "SPN" SG_ 2365462526 AxlrVlv07EstmtdFlwHghRsltn 9739;
BA_ "SPN" SG_ 2365462782 AxlrVlvNmr08ExtndPrtEstmtdFlw 1997;
BA_ "SPN" SG_ 2365462782 AxlrVlvNmr08RtrtPrtEstmtdFlw 1998;
BA_ "SPN" SG_ 2365462782 AxlrVlvNmr08VlvStt 1999;
BA_ "SPN" SG_ 2365462782 AuxiliaryValve08FailSafeMode 2262;
BA_ "SPN" SG_ 2365462782 AxlrVlvNmr08EstmtdFlwLmtStts 5177;
BA_ "SPN" SG_ 2365462782 AuxiliaryValve08ExitReasonCode 5808;
BA_ "SPN" SG_ 2365462782 AxlrVlv08EstmtdFlwHghRsltn 9740;
BA_ "SPN" SG_ 2365463038 AxlrVlvNmr09ExtndPrtEstmtdFlw 2265;
BA_ "SPN" SG_ 2365463038 AxlrVlvNmr09RtrtPrtEstmtdFlw 2266;
BA_ "SPN" SG_ 2365463038 AxlrVlvNmr09VlvStt 2267;
BA_ "SPN" SG_ 2365463038 AuxiliaryValve09FailSafeMode 2274;
BA_ "SPN" SG_ 2365463038 AxlrVlvNmr09EstmtdFlwLmtStts 5179;
BA_ "SPN" SG_ 2365463038 AuxiliaryValve09ExitReasonCode 5809;
BA_ "SPN" SG_ 2365463038 AxlrVlv09EstmtdFlwHghRsltn 9741;
BA_ "SPN" SG_ 2365463294 AxlrVlvNmr10ExtndPrtEstmtdFlw 2277;
BA_ "SPN" SG_ 2365463294 AxlrVlvNmr10RtrtPrtEstmtdFlw 2278;
BA_ "SPN" SG_ 2365463294 AxlrVlvNmr10VlvStt 2279;
BA_ "SPN" SG_ 2365463294 AuxiliaryValve10FailSafeMode 2286;
BA_ "SPN" SG_ 2365463294 AxlrVlvNmr10EstmtdFlwLmtStts 5181;
BA_ "SPN" SG_ 2365463294 AuxiliaryValve10ExitReasonCode 5810;
BA_ "SPN" SG_ 2365463294 AxlrVlv10EstmtdFlwHghRsltn 9742;
BA_ "SPN" SG_ 2365463550 AxlrVlvNmr11ExtndPrtEstmtdFlw 2289;
BA_ "SPN" SG_ 2365463550 AxlrVlvNmr11RtrtPrtEstmtdFlw 2290;
BA_ "SPN" SG_ 2365463550 AxlrVlvNmr11VlvStt 2291;
BA_ "SPN" SG_ 2365463550 AuxiliaryValve11FailSafeMode 2298;
BA_ "SPN" SG_ 2365463550 AxlrVlvNmr11EstmtdFlwLmtStts 5183;
BA_ "SPN" SG_ 2365463550 AuxiliaryValve11ExitReasonCode 5811;
BA_ "SPN" SG_ 2365463550 AxlrVlv11EstmtdFlwHghRsltn 9743;
BA_ "SPN" SG_ 2365463806 AxlrVlvNmr12ExtndPrtEstmtdFlw 2301;
BA_ "SPN" SG_ 2365463806 AxlrVlvNmr12RtrtPrtEstmtdFlw 2302;
BA_ "SPN" SG_ 2365463806 AxlrVlvNmr12VlvStt 2303;
BA_ "SPN" SG_ 2365463806 AuxiliaryValve12FailSafeMode 2310;
BA_ "SPN" SG_ 2365463806 AxlrVlvNmr12EstmtdFlwLmtStts 5185;
BA_ "SPN" SG_ 2365463806 AuxiliaryValve12ExitReasonCode 5812;
BA_ "SPN" SG_ 2365463806 AxlrVlv12EstmtdFlwHghRsltn 9744;
BA_ "SPN" SG_ 2365464062 AxlrVlvNmr13ExtndPrtEstmtdFlw 2313;
BA_ "SPN" SG_ 2365464062 AxlrVlvNmr13RtrtPrtEstmtdFlw 2314;
BA_ "SPN" SG_ 2365464062 AxlrVlvNmr13VlvStt 2315;
BA_ "SPN" SG_ 2365464062 AuxiliaryValve13FailSafeMode 2322;
BA_ "SPN" SG_ 2365464062 AxlrVlvNmr13EstmtdFlwLmtStts 5187;
BA_ "SPN" SG_ 2365464062 AuxiliaryValve13ExitReasonCode 5813;
BA_ "SPN" SG_ 2365464062 AxlrVlv13EstmtdFlwHghRsltn 9745;
BA_ "SPN" SG_ 2365464318 AxlrVlvNmr14ExtndPrtEstmtdFlw 2325;
BA_ "SPN" SG_ 2365464318 AxlrVlvNmr14RtrtPrtEstmtdFlw 2326;
BA_ "SPN" SG_ 2365464318 AxlrVlvNmr14VlvStt 2327;
BA_ "SPN" SG_ 2365464318 AuxiliaryValve14FailSafeMode 2334;
BA_ "SPN" SG_ 2365464318 AxlrVlvNmr14EstmtdFlwLmtStts 5189;
BA_ "SPN" SG_ 2365464318 AuxiliaryValve14ExitReasonCode 5814;
BA_ "SPN" SG_ 2365464318 AxlrVlv14EstmtdFlwHghRsltn 9746;
BA_ "SPN" SG_ 2365464574 AxlrVlvNmr15ExtndPrtEstmtdFlw 2337;
BA_ "SPN" SG_ 2365464574 AxlrVlvNmr15RtrtPrtEstmtdFlw 2338;
BA_ "SPN" SG_ 2365464574 AxlrVlvNmr15VlvStt 2339;
BA_ "SPN" SG_ 2365464574 AuxiliaryValve15FailSafeMode 2346;
BA_ "SPN" SG_ 2365464574 AxlrVlvNmr15EstmtdFlwLmtStts 5191;
BA_ "SPN" SG_ 2365464574 AuxiliaryValve15ExitReasonCode 5815;
BA_ "SPN" SG_ 2365464574 AxlrVlv15EstmtdFlwHghRsltn 9747;
BA_ "SPN" SG_ 2365464830 AxlrVlvNmr0ExtndPrtMsrdFlw 1899;
BA_ "SPN" SG_ 2365464830 AxlrVlvNmr0RtrtPrtMsrdFlw 1900;
BA_ "SPN" SG_ 2365464830 AxlrVlvNmr0RtrnPrtPrssr 1906;
BA_ "SPN" SG_ 2365464830 AxlrVlvNmr0ExtndPrtPrssr 1904;
BA_ "SPN" SG_ 2365464830 AxlrVlv0RtrtPrtPrssr 1905;
BA_ "SPN" SG_ 2365464830 AxlrVlvNmr0MsrdFlwLmtStts 5160;
BA_ "SPN" SG_ 2365465086 AxlrVlvNmr01ExtndPrtMsrdFlw 1911;
BA_ "SPN" SG_ 2365465086 AxlrVlvNmr01RtrtPrtMsrdFlw 1912;
BA_ "SPN" SG_ 2365465086 AxlrVlvNmr01RtrnPrtPrssr 1918;
BA_ "SPN" SG_ 2365465086 AxlrVlvNmr01ExtndPrtPrssr 1916;
BA_ "SPN" SG_ 2365465086 AxlrVlvNmr01RtrtPrtPrssr 1917;
BA_ "SPN" SG_ 2365465086 AxlrVlvNmr01MsrdFlwLmtStts 5162;
BA_ "SPN" SG_ 2365465342 AxlrVlvNmr02ExtndPrtMsrdFlw 1923;
BA_ "SPN" SG_ 2365465342 AxlrVlvNmr02RtrtPrtMsrdFlw 1924;
BA_ "SPN" SG_ 2365465342 AxlrVlvNmr02RtrnPrtPrssr 1930;
BA_ "SPN" SG_ 2365465342 AxlrVlvNmr02ExtndPrtPrssr 1928;
BA_ "SPN" SG_ 2365465342 AxlrVlvNmr02RtrtPrtPrssr 1929;
BA_ "SPN" SG_ 2365465342 AxlrVlvNmr02MsrdFlwLmtStts 5164;
BA_ "SPN" SG_ 2365465598 AxlrVlvNmr03ExtndPrtMsrdFlw 1935;
BA_ "SPN" SG_ 2365465598 AxlrVlvNmr03RtrtPrtMsrdFlw 1936;
BA_ "SPN" SG_ 2365465598 AxlrVlvNmr03RtrnPrtPrssr 1942;
BA_ "SPN" SG_ 2365465598 AxlrVlvNmr03ExtndPrtPrssr 1940;
BA_ "SPN" SG_ 2365465598 AxlrVlvNmr03RtrtPrtPrssr 1941;
BA_ "SPN" SG_ 2365465598 AxlrVlvNmr03MsrdFlwLmtStts 5166;
BA_ "SPN" SG_ 2365465854 AxlrVlvNmr04ExtndPrtMsrdFlw 1947;
BA_ "SPN" SG_ 2365465854 AxlrVlvNmr04RtrtPrtMsrdFlw 1948;
BA_ "SPN" SG_ 2365465854 AxlrVlvNmr04RtrnPrtPrssr 1954;
BA_ "SPN" SG_ 2365465854 AxlrVlvNmr04ExtndPrtPrssr 1952;
BA_ "SPN" SG_ 2365465854 AxlrVlvNmr04RtrtPrtPrssr 1953;
BA_ "SPN" SG_ 2365465854 AxlrVlvNmr04MsrdFlwLmtStts 5168;
BA_ "SPN" SG_ 2365466110 AxlrVlvNmr05ExtndPrtMsrdFlw 1959;
BA_ "SPN" SG_ 2365466110 AxlrVlvNmr05RtrtPrtMsrdFlw 1960;
BA_ "SPN" SG_ 2365466110 AxlrVlvNmr05RtrnPrtPrssr 1966;
BA_ "SPN" SG_ 2365466110 AxlrVlvNmr05ExtndPrtPrssr 1964;
BA_ "SPN" SG_ 2365466110 AxlrVlvNmr05RtrtPrtPrssr 1965;
BA_ "SPN" SG_ 2365466110 AxlrVlvNmr05MsrdFlwLmtStts 5170;
BA_ "SPN" SG_ 2365466366 AxlrVlvNmr06ExtndPrtMsrdFlw 1971;
BA_ "SPN" SG_ 2365466366 AxlrVlvNmr06RtrtPrtMsrdFlw 1972;
BA_ "SPN" SG_ 2365466366 AxlrVlvNmr06RtrnPrtPrssr 1978;
BA_ "SPN" SG_ 2365466366 AxlrVlvNmr06ExtndPrtPrssr 1976;
BA_ "SPN" SG_ 2365466366 AxlrVlvNmr06RtrtPrtPrssr 1977;
BA_ "SPN" SG_ 2365466366 AxlrVlvNmr06MsrdFlwLmtStts 5172;
BA_ "SPN" SG_ 2365466622 AxlrVlvNmr07ExtndPrtMsrdFlw 1983;
BA_ "SPN" SG_ 2365466622 AxlrVlvNmr07RtrtPrtMsrdFlw 1984;
BA_ "SPN" SG_ 2365466622 AxlrVlvNmr07RtrnPrtPrssr 1990;
BA_ "SPN" SG_ 2365466622 AxlrVlvNmr07ExtndPrtPrssr 1988;
BA_ "SPN" SG_ 2365466622 AxlrVlvNmr07RtrtPrtPrssr 1989;
BA_ "SPN" SG_ 2365466622 AxlrVlvNmr07MsrdFlwLmtStts 5174;
BA_ "SPN" SG_ 2365466878 AxlrVlvNmr08ExtndPrtMsrdFlw 1995;
BA_ "SPN" SG_ 2365466878 AxlrVlvNmr08RtrtPrtMsrdFlw 1996;
BA_ "SPN" SG_ 2365466878 AxlrVlvNmr08RtrnPrtPrssr 2258;
BA_ "SPN" SG_ 2365466878 AxlrVlvNmr08ExtndPrtPrssr 2256;
BA_ "SPN" SG_ 2365466878 AxlrVlvNmr08RtrtPrtPrssr 2257;
BA_ "SPN" SG_ 2365466878 AxlrVlvNmr08MsrdFlwLmtStts 5176;
BA_ "SPN" SG_ 2365467134 AxlrVlvNmr09ExtndPrtMsrdFlw 2263;
BA_ "SPN" SG_ 2365467134 AxlrVlvNmr09RtrtPrtMsrdFlw 2264;
BA_ "SPN" SG_ 2365467134 AxlrVlvNmr09RtrnPrtPrssr 2270;
BA_ "SPN" SG_ 2365467134 AxlrVlvNmr09ExtndPrtPrssr 2268;
BA_ "SPN" SG_ 2365467134 AxlrVlvNmr09RtrtPrtPrssr 2269;
BA_ "SPN" SG_ 2365467134 AxlrVlvNmr09MsrdFlwLmtStts 5178;
BA_ "SPN" SG_ 2365467390 AxlrVlvNmr10ExtndPrtMsrdFlw 2275;
BA_ "SPN" SG_ 2365467390 AxlrVlvNmr10RtrtPrtMsrdFlw 2276;
BA_ "SPN" SG_ 2365467390 AxlrVlvNmr10RtrnPrtPrssr 2282;
BA_ "SPN" SG_ 2365467390 AxlrVlvNmr10ExtndPrtPrssr 2280;
BA_ "SPN" SG_ 2365467390 AxlrVlvNmr10RtrtPrtPrssr 2281;
BA_ "SPN" SG_ 2365467390 AxlrVlvNmr10MsrdFlwLmtStts 5180;
BA_ "SPN" SG_ 2365467646 AxlrVlvNmr11ExtndPrtMsrdFlw 2287;
BA_ "SPN" SG_ 2365467646 AxlrVlvNmr11RtrtPrtMsrdFlw 2288;
BA_ "SPN" SG_ 2365467646 AxlrVlvNmr11RtrnPrtPrssr 2294;
BA_ "SPN" SG_ 2365467646 AxlrVlvNmr11ExtndPrtPrssr 2292;
BA_ "SPN" SG_ 2365467646 AxlrVlvNmr11RtrtPrtPrssr 2293;
BA_ "SPN" SG_ 2365467646 AxlrVlvNmr11MsrdFlwLmtStts 5182;
BA_ "SPN" SG_ 2365467902 AxlrVlvNmr12ExtndPrtMsrdFlw 2299;
BA_ "SPN" SG_ 2365467902 AxlrVlvNmr12RtrtPrtMsrdFlw 2300;
BA_ "SPN" SG_ 2365467902 AxlrVlvNmr12RtrnPrtPrssr 2306;
BA_ "SPN" SG_ 2365467902 AxlrVlvNmr12ExtndPrtPrssr 2304;
BA_ "SPN" SG_ 2365467902 AxlrVlvNmr12RtrtPrtPrssr 2305;
BA_ "SPN" SG_ 2365467902 AxlrVlvNmr12MsrdFlwLmtStts 5184;
BA_ "SPN" SG_ 2365468158 AxlrVlvNmr13ExtndPrtMsrdFlw 2311;
BA_ "SPN" SG_ 2365468158 AxlrVlvNmr13RtrtPrtMsrdFlw 2312;
BA_ "SPN" SG_ 2365468158 AxlrVlvNmr13RtrnPrtPrssr 2318;
BA_ "SPN" SG_ 2365468158 AxlrVlvNmr13ExtndPrtPrssr 2316;
BA_ "SPN" SG_ 2365468158 AxlrVlvNmr13RtrtPrtPrssr 2317;
BA_ "SPN" SG_ 2365468158 AxlrVlvNmr13MsrdFlwLmtStts 5186;
BA_ "SPN" SG_ 2365468414 AxlrVlvNmr14ExtndPrtMsrdFlw 2323;
BA_ "SPN" SG_ 2365468414 AxlrVlvNmr14RtrtPrtMsrdFlw 2324;
BA_ "SPN" SG_ 2365468414 AxlrVlvNmr14RtrnPrtPrssr 2330;
BA_ "SPN" SG_ 2365468414 AxlrVlvNmr14ExtndPrtPrssr 2328;
BA_ "SPN" SG_ 2365468414 AxlrVlvNmr14RtrtPrtPrssr 2329;
BA_ "SPN" SG_ 2365468414 AxlrVlvNmr14MsrdFlwLmtStts 5188;
BA_ "SPN" SG_ 2365468670 AxlrVlvNmr15ExtndPrtMsrdFlw 2335;
BA_ "SPN" SG_ 2365468670 AxlrVlvNmr15RtrtPrtMsrdFlw 2336;
BA_ "SPN" SG_ 2365468670 AxlrVlvNmr15RtrnPrtPrssr 2342;
BA_ "SPN" SG_ 2365468670 AxlrVlvNmr15ExtndPrtPrssr 2340;
BA_ "SPN" SG_ 2365468670 AxlrVlvNmr15RtrtPrtPrssr 2341;
BA_ "SPN" SG_ 2365468670 AxlrVlvNmr15MsrdFlwLmtStts 5190;
BA_ "SPN" SG_ 2365468926 AxlrVlvNmr0PrtFlwCmmnd 1907;
BA_ "SPN" SG_ 2365468926 AxlrVlvNmr0RsltnMdCmmnd 7872;
BA_ "SPN" SG_ 2365468926 AxlrVlvNmr0SttCmmnd 1908;
BA_ "SPN" SG_ 2365468926 AxlrVlvNmr0FlSfMdCmmnd 1909;
BA_ "SPN" SG_ 2365468926 AxVvN0PtFwExtddRstCd 7856;
BA_ "SPN" SG_ 2365469182 AxlrVlvNmr1PrtFlwCmmnd 1919;
BA_ "SPN" SG_ 2365469182 AxlrVlvNmr1RsltnMdCmmnd 7873;
BA_ "SPN" SG_ 2365469182 AxlrVlvNmr1SttCmmnd 1920;
BA_ "SPN" SG_ 2365469182 AxlrVlvNmr1FlSfMdCmmnd 1921;
BA_ "SPN" SG_ 2365469182 AxVvN1PtFwExtddRstCd 7857;
BA_ "SPN" SG_ 2365469438 AxlrVlvNmr2PrtFlwCmmnd 1931;
BA_ "SPN" SG_ 2365469438 AxlrVlvNmr2RsltnMdCmmnd 7874;
BA_ "SPN" SG_ 2365469438 AxlrVlvNmr2SttCmmnd 1932;
BA_ "SPN" SG_ 2365469438 AxlrVlvNmr2FlSfMdCmmnd 1933;
BA_ "SPN" SG_ 2365469438 AxVvN2PtFwExtddRstCd 7858;
BA_ "SPN" SG_ 2365469694 AxlrVlvNmr3PrtFlwCmmnd 1943;
BA_ "SPN" SG_ 2365469694 AxlrVlvNmr3RsltnMdCmmnd 7875;
BA_ "SPN" SG_ 2365469694 AxlrVlvNmr3SttCmmnd 1944;
BA_ "SPN" SG_ 2365469694 AxlrVlvNmr3FlSfMdCmmnd 1945;
BA_ "SPN" SG_ 2365469694 AxVvN3PtFwExtddRstCd 7859;
BA_ "SPN" SG_ 2365469950 AxlrVlvNmr4PrtFlwCmmnd 1955;
BA_ "SPN" SG_ 2365469950 AxlrVlvNmr4RsltnMdCmmnd 7876;
BA_ "SPN" SG_ 2365469950 AxlrVlvNmr4SttCmmnd 1956;
BA_ "SPN" SG_ 2365469950 AxlrVlvNmr4FlSfMdCmmnd 1957;
BA_ "SPN" SG_ 2365469950 AxVvN4PtFwExtddRstCd 7860;
BA_ "SPN" SG_ 2365470206 AxlrVlvNmr5PrtFlwCmmnd 1967;
BA_ "SPN" SG_ 2365470206 AxlrVlvNmr5RsltnMdCmmnd 7877;
BA_ "SPN" SG_ 2365470206 AxlrVlvNmr5SttCmmnd 1968;
BA_ "SPN" SG_ 2365470206 AxlrVlvNmr5FlSfMdCmmnd 1969;
BA_ "SPN" SG_ 2365470206 AxVvN5PtFwExtddRstCd 7861;
BA_ "SPN" SG_ 2365470462 AxlrVlvNmr6PrtFlwCmmnd 1979;
BA_ "SPN" SG_ 2365470462 AxlrVlvNmr6RsltnMdCmmnd 7878;
BA_ "SPN" SG_ 2365470462 AxlrVlvNmr6SttCmmnd 1980;
BA_ "SPN" SG_ 2365470462 AxlrVlvNmr6FlSfMdCmmnd 1981;
BA_ "SPN" SG_ 2365470462 AxVvN6PtFwExtddRstCd 7862;
BA_ "SPN" SG_ 2365470718 AxlrVlvNmr7PrtFlwCmmnd 1991;
BA_ "SPN" SG_ 2365470718 AxlrVlvNmr7RsltnMdCmmnd 7879;
BA_ "SPN" SG_ 2365470718 AxlrVlvNmr7SttCmmnd 1992;
BA_ "SPN" SG_ 2365470718 AxlrVlvNmr7FlSfMdCmmnd 1993;
BA_ "SPN" SG_ 2365470718 AxVvN7PtFwExtddRstCd 7863;
BA_ "SPN" SG_ 2365470974 AxlrVlvNmr8PrtFlwCmmnd 2259;
BA_ "SPN" SG_ 2365470974 AxlrVlvNmr8RsltnMdCmmnd 7880;
BA_ "SPN" SG_ 2365470974 AxlrVlvNmr8SttCmmnd 2260;
BA_ "SPN" SG_ 2365470974 AxlrVlvNmr8FlSfMdCmmnd 2261;
BA_ "SPN" SG_ 2365470974 AxVvN8PtFwExtddRstCd 7864;
BA_ "SPN" SG_ 2365471230 AxlrVlvNmr9PrtFlwCmmnd 2271;
BA_ "SPN" SG_ 2365471230 AxlrVlvNmr9RsltnMdCmmnd 7881;
BA_ "SPN" SG_ 2365471230 AxlrVlvNmr9SttCmmnd 2272;
BA_ "SPN" SG_ 2365471230 AxlrVlvNmr9FlSfMdCmmnd 2273;
BA_ "SPN" SG_ 2365471230 AxVvN9PtFwExtddRstCd 7865;
BA_ "SPN" SG_ 2365471486 AxlrVlvNmr10PrtFlwCmmnd 2283;
BA_ "SPN" SG_ 2365471486 AxlrVlvNmr10RsltnMdCmmnd 7882;
BA_ "SPN" SG_ 2365471486 AxlrVlvNmr10SttCmmnd 2284;
BA_ "SPN" SG_ 2365471486 AxlrVlvNmr10FlSfMdCmmnd 2285;
BA_ "SPN" SG_ 2365471486 AxVvN10PtFwExtddRstCd 7866;
BA_ "SPN" SG_ 2365471742 AxlrVlvNmr11PrtFlwCmmnd 2295;
BA_ "SPN" SG_ 2365471742 AxlrVlvNmr11RsltnMdCmmnd 7883;
BA_ "SPN" SG_ 2365471742 AxlrVlvNmr11SttCmmnd 2296;
BA_ "SPN" SG_ 2365471742 AxlrVlvNmr11FlSfMdCmmnd 2297;
BA_ "SPN" SG_ 2365471742 AxVvN11PtFwExtddRstCd 7867;
BA_ "SPN" SG_ 2365471998 AxlrVlvNmr12PrtFlwCmmnd 2307;
BA_ "SPN" SG_ 2365471998 AxlrVlvNmr12RsltnMdCmmnd 7884;
BA_ "SPN" SG_ 2365471998 AxlrVlvNmr12SttCmmnd 2308;
BA_ "SPN" SG_ 2365471998 AxlrVlvNmr12FlSfMdCmmnd 2309;
BA_ "SPN" SG_ 2365471998 AxVvN12PtFwExtddRstCd 7868;
BA_ "SPN" SG_ 2365472254 AxlrVlvNmr13PrtFlwCmmnd 2319;
BA_ "SPN" SG_ 2365472254 AxlrVlvNmr13RsltnMdCmmnd 7885;
BA_ "SPN" SG_ 2365472254 AxlrVlvNmr13SttCmmnd 2320;
BA_ "SPN" SG_ 2365472254 AxlrVlvNmr13FlSfMdCmmnd 2321;
BA_ "SPN" SG_ 2365472254 AxVvN13PtFwExtddRstCd 7869;
BA_ "SPN" SG_ 2365472510 AxlrVlvNmr14PrtFlwCmmnd 2331;
BA_ "SPN" SG_ 2365472510 AxlrVlvNmr14RsltnMdCmmnd 7886;
BA_ "SPN" SG_ 2365472510 AxlrVlvNmr14SttCmmnd 2332;
BA_ "SPN" SG_ 2365472510 AxlrVlvNmr14FlSfMdCmmnd 2333;
BA_ "SPN" SG_ 2365472510 AxVvN14PtFwExtddRstCd 7870;
BA_ "SPN" SG_ 2365472766 AxlrVlvNmr15PrtFlwCmmnd 2343;
BA_ "SPN" SG_ 2365472766 AxlrVlvNmr15RsltnMdCmmnd 7887;
BA_ "SPN" SG_ 2365472766 AxlrVlvNmr15SttCmmnd 2344;
BA_ "SPN" SG_ 2365472766 AxlrVlvNmr15FlSfMdCmmnd 2345;
BA_ "SPN" SG_ 2365472766 AxVvN15PtFwExtddRstCd 7871;
BA_ "SPN" SG_ 2365473534 FrontHitchPositionCommand 1874;
BA_ "SPN" SG_ 2365473534 RearHitchPositionCommand 1875;
BA_ "SPN" SG_ 2365473534 FrntPtOtptShftSpdStPntCmmnd 1886;
BA_ "SPN" SG_ 2365473534 RrPtOtptShftSpdStPntCmmnd 1887;
BA_ "SPN" SG_ 2365473534 RearPtoEngagementCommand 1894;
BA_ "SPN" SG_ 2365473534 FrontPtoEngagementCommand 1893;
BA_ "SPN" SG_ 2365473534 RearPtoEconomyModeCommand 1898;
BA_ "SPN" SG_ 2365473534 FrontPtoEconomyModeCommand 1897;
BA_ "SPN" SG_ 2365473534 RearPtoModeCommand 1896;
BA_ "SPN" SG_ 2365473534 FrontPtoModeCommand 1895;
BA_ "SPN" SG_ 2365473790 RearPtoOutputShaftSpeed 1883;
BA_ "SPN" SG_ 2365473790 RearPtoOutputShaftSpeedSetPoint 1885;
BA_ "SPN" SG_ 2365473790 RearPtoEngagementRequestStatus 5156;
BA_ "SPN" SG_ 2365473790 RearPowerTakeOffEconomyMode 1892;
BA_ "SPN" SG_ 2365473790 RearPowerTakeOffMode 1890;
BA_ "SPN" SG_ 2365473790 RearPowerTakeOffEngagement 2408;
BA_ "SPN" SG_ 2365473790 RearPtoShaftSpeedLimitStatus 5159;
BA_ "SPN" SG_ 2365473790 RearPtoEconomyModeRequestStatus 5158;
BA_ "SPN" SG_ 2365473790 RearPtoModeRequestStatus 5157;
BA_ "SPN" SG_ 2365473790 RearPtoExitReasonCode 5820;
BA_ "SPN" SG_ 2365474046 FrontPtoOutputShaftSpeed 1882;
BA_ "SPN" SG_ 2365474046 FrntPtOtptShftSpdStPnt 1884;
BA_ "SPN" SG_ 2365474046 FrontPtoEngagementRequestStatus 5152;
BA_ "SPN" SG_ 2365474046 FrontPowerTakeOffEconomyMode 1891;
BA_ "SPN" SG_ 2365474046 FrontPowerTakeOffMode 1889;
BA_ "SPN" SG_ 2365474046 FrontPowerTakeOffEngagement 1888;
BA_ "SPN" SG_ 2365474046 FrontPtoShaftSpeedLimitStatus 5155;
BA_ "SPN" SG_ 2365474046 FrntPtEnmMdRqstStts 5154;
BA_ "SPN" SG_ 2365474046 FrontPtoModeRequestStatus 5153;
BA_ "SPN" SG_ 2365474046 FrontPtoExitReasonCode 5817;
BA_ "SPN" SG_ 2365474302 RearHitchPosition 1873;
BA_ "SPN" SG_ 2365474302 RearHitchPositionLimitStatus 5151;
BA_ "SPN" SG_ 2365474302 RearHitchInWorkIndication 1877;
BA_ "SPN" SG_ 2365474302 RearNominalLowerLinkForce 1881;
BA_ "SPN" SG_ 2365474302 RearDraft 1879;
BA_ "SPN" SG_ 2365474302 RearHitchExitReasonCode 5819;
BA_ "SPN" SG_ 2365474558 FrontHitchPosition 1872;
BA_ "SPN" SG_ 2365474558 FrontHitchPositionLimitStatus 5150;
BA_ "SPN" SG_ 2365474558 FrontHitchInWorkIndication 1876;
BA_ "SPN" SG_ 2365474558 FrontNominalLowerLinkForce 1880;
BA_ "SPN" SG_ 2365474558 FrontDraft 1878;
BA_ "SPN" SG_ 2365474558 FrontHitchExitReasonCode 5816;
BA_ "SPN" SG_ 2566801406 MaintainAcuatorPower 1868;
BA_ "SPN" SG_ 2566801406 MaintainEcuPower 1867;
BA_ "SPN" SG_ 2566801406 ImplementInWorkState 7447;
BA_ "SPN" SG_ 2566801406 ImplementReadyToWorkState 1871;
BA_ "SPN" SG_ 2566801406 ImplementParkState 1870;
BA_ "SPN" SG_ 2566801406 ImplementTransportState 1869;
BA_ "SPN" SG_ 2365475070 WheelBasedMachineSpeed 1862;
BA_ "SPN" SG_ 2365475070 WheelBasedMachineDistance 1863;
BA_ "SPN" SG_ 2365475070 MaximumTimeOfTractorPower 1866;
BA_ "SPN" SG_ 2365475070 WheelBasedMachineDirection 1864;
BA_ "SPN" SG_ 2365475070 KeySwitchState 1865;
BA_ "SPN" SG_ 2365475070 ImplementStartStopOperations 5203;
BA_ "SPN" SG_ 2365475070 OperatorDirectionReversed 5244;
BA_ "SPN" SG_ 2365475326 GroundBasedMachineSpeed 1859;
BA_ "SPN" SG_ 2365475326 GroundBasedMachineDistance 1860;
BA_ "SPN" SG_ 2365475326 GroundBasedMachineDirection 1861;
